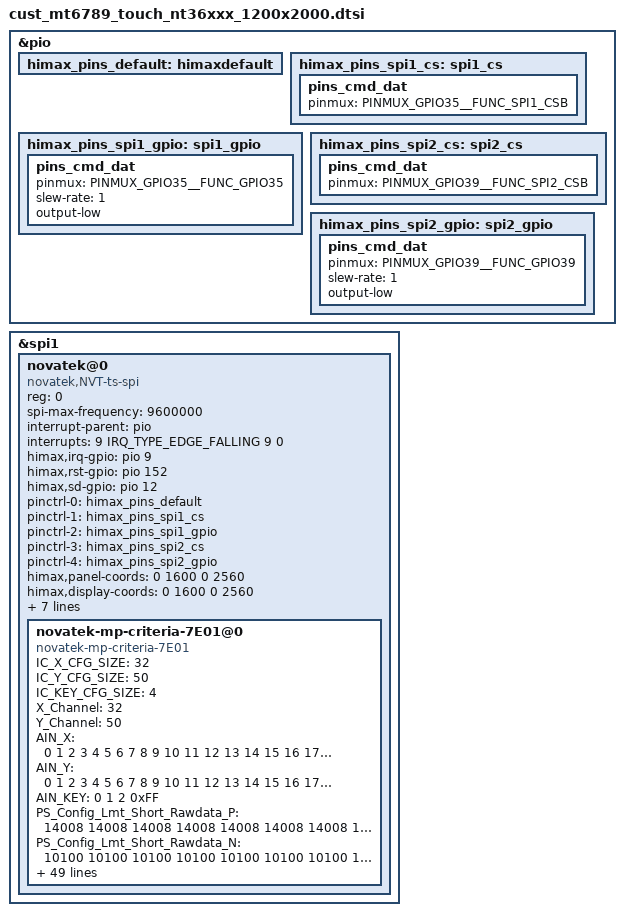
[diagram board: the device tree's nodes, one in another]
// SPDX-License-Identifier: GPL-2.0
/*
 * Copyright (c) 2022 MediaTek Inc.
 *
 */

&pio {
	himax_pins_default: himaxdefault {
	};

	himax_pins_spi1_cs: spi1_cs {
		pins_cmd_dat {
			pinmux = <PINMUX_GPIO35__FUNC_SPI1_CSB>;
		};
	};

	himax_pins_spi1_gpio: spi1_gpio {
		pins_cmd_dat {
			pinmux = <PINMUX_GPIO35__FUNC_GPIO35>;
			slew-rate = <1>;
			output-low;
		};
	};
	himax_pins_spi2_cs: spi2_cs {
		pins_cmd_dat {
			pinmux = <PINMUX_GPIO39__FUNC_SPI2_CSB>;
		};
	};

	himax_pins_spi2_gpio: spi2_gpio {
		pins_cmd_dat {
			pinmux = <PINMUX_GPIO39__FUNC_GPIO39>;
			slew-rate = <1>;
			output-low;
		};
	};
};

&spi1 {
	status = "okay";
	#address-cells = <1>;
	#size-cells = <0>;
	novatek@0{
		compatible = "novatek,NVT-ts-spi";//,"himax,hxcommon" ;
		reg = <0>; //Same as CS ID
		status = "okay";
		//4800000,9600000,15000000,19200000
		spi-max-frequency = <9600000>;	
        interrupt-parent = <&pio>;
        interrupts = <9 IRQ_TYPE_EDGE_FALLING 9 0>;
        himax,irq-gpio = <&pio 9 0x0>;
        himax,rst-gpio = <&pio 152 0x0>;
        himax,sd-gpio = <&pio 12 0x0>;
        pinctrl-names = "default", "spi1_cs", "spi1_gpio", "spi2_cs", "spi2_gpio";
        pinctrl-0 = <&himax_pins_default>;
        pinctrl-1 = <&himax_pins_spi1_cs>;
        pinctrl-2 = <&himax_pins_spi1_gpio>;
        pinctrl-3 = <&himax_pins_spi2_cs>;
        pinctrl-4 = <&himax_pins_spi2_gpio>;
        himax,panel-coords = <0 1600 0 2560>;
        himax,display-coords = <0 1600 0 2560>;
		novatek,reset-gpio = <&pio 152 0x00>;
		novatek,irq-gpio = <&pio 9 0x00>;
		novatek,pen-support;
		novatek,stylus-resol-double;
		
	  /* 525 */
		//novatek,swrst-n8-addr = <0x01F01A>;
		/* 672A, 525B, 675, 526 */
		novatek,swrst-n8-addr = <0x03F0FE>;
		novatek,spi-rd-fast-addr = <0x03F310>;
		
		/* MP */
		novatek,mp-support-dt;
		
		novatek-mp-criteria-7E01@0 {
			#address-cells = <1>;
			#size-cells = <0>;
			compatible = "novatek-mp-criteria-7E01";

			/* MP Config */
			IC_X_CFG_SIZE = <32>;
			IC_Y_CFG_SIZE = <50>;
			IC_KEY_CFG_SIZE = <4>;
			X_Channel = <32>;
			Y_Channel = <50>;
			AIN_X = <0 1 2 3 4 5 6 7 8 9 10 11 12 13 14 15 16 17 18 19 20 21 22 23 24 25 26 27 28 29 30 31>;
			AIN_Y = <0 1 2 3 4 5 6 7 8 9 10 11 12 13 14 15 16 17 18 19 20 21 22 23 24 25 26 27 28 29 30 31 32 33 34 35 36 37 38 39 40 41 42 43 44 45 46 47 48 49>;
			AIN_KEY = <0 1 2 0xFF>;

			/* MP Criteria */
			PS_Config_Lmt_Short_Rawdata_P = <
				14008 14008 14008 14008 14008 14008 14008 14008 14008 14008 14008 14008 14008 14008 14008 14008 14008 14008 14008 14008 14008 14008 14008 14008 14008 14008 14008 14008 14008 14008 14008 14008
				14008 14008 14008 14008 14008 14008 14008 14008 14008 14008 14008 14008 14008 14008 14008 14008 14008 14008 14008 14008 14008 14008 14008 14008 14008 14008 14008 14008 14008 14008 14008 14008
				14008 14008 14008 14008 14008 14008 14008 14008 14008 14008 14008 14008 14008 14008 14008 14008 14008 14008 14008 14008 14008 14008 14008 14008 14008 14008 14008 14008 14008 14008 14008 14008
				14008 14008 14008 14008 14008 14008 14008 14008 14008 14008 14008 14008 14008 14008 14008 14008 14008 14008 14008 14008 14008 14008 14008 14008 14008 14008 14008 14008 14008 14008 14008 14008
				14008 14008 14008 14008 14008 14008 14008 14008 14008 14008 14008 14008 14008 14008 14008 14008 14008 14008 14008 14008 14008 14008 14008 14008 14008 14008 14008 14008 14008 14008 14008 14008
				14008 14008 14008 14008 14008 14008 14008 14008 14008 14008 14008 14008 14008 14008 14008 14008 14008 14008 14008 14008 14008 14008 14008 14008 14008 14008 14008 14008 14008 14008 14008 14008
				14008 14008 14008 14008 14008 14008 14008 14008 14008 14008 14008 14008 14008 14008 14008 14008 14008 14008 14008 14008 14008 14008 14008 14008 14008 14008 14008 14008 14008 14008 14008 14008
				14008 14008 14008 14008 14008 14008 14008 14008 14008 14008 14008 14008 14008 14008 14008 14008 14008 14008 14008 14008 14008 14008 14008 14008 14008 14008 14008 14008 14008 14008 14008 14008
				14008 14008 14008 14008 14008 14008 14008 14008 14008 14008 14008 14008 14008 14008 14008 14008 14008 14008 14008 14008 14008 14008 14008 14008 14008 14008 14008 14008 14008 14008 14008 14008
				14008 14008 14008 14008 14008 14008 14008 14008 14008 14008 14008 14008 14008 14008 14008 14008 14008 14008 14008 14008 14008 14008 14008 14008 14008 14008 14008 14008 14008 14008 14008 14008
				14008 14008 14008 14008 14008 14008 14008 14008 14008 14008 14008 14008 14008 14008 14008 14008 14008 14008 14008 14008 14008 14008 14008 14008 14008 14008 14008 14008 14008 14008 14008 14008
				14008 14008 14008 14008 14008 14008 14008 14008 14008 14008 14008 14008 14008 14008 14008 14008 14008 14008 14008 14008 14008 14008 14008 14008 14008 14008 14008 14008 14008 14008 14008 14008
				14008 14008 14008 14008 14008 14008 14008 14008 14008 14008 14008 14008 14008 14008 14008 14008 14008 14008 14008 14008 14008 14008 14008 14008 14008 14008 14008 14008 14008 14008 14008 14008
				14008 14008 14008 14008 14008 14008 14008 14008 14008 14008 14008 14008 14008 14008 14008 14008 14008 14008 14008 14008 14008 14008 14008 14008 14008 14008 14008 14008 14008 14008 14008 14008
				14008 14008 14008 14008 14008 14008 14008 14008 14008 14008 14008 14008 14008 14008 14008 14008 14008 14008 14008 14008 14008 14008 14008 14008 14008 14008 14008 14008 14008 14008 14008 14008
				14008 14008 14008 14008 14008 14008 14008 14008 14008 14008 14008 14008 14008 14008 14008 14008 14008 14008 14008 14008 14008 14008 14008 14008 14008 14008 14008 14008 14008 14008 14008 14008
				14008 14008 14008 14008 14008 14008 14008 14008 14008 14008 14008 14008 14008 14008 14008 14008 14008 14008 14008 14008 14008 14008 14008 14008 14008 14008 14008 14008 14008 14008 14008 14008
				14008 14008 14008 14008 14008 14008 14008 14008 14008 14008 14008 14008 14008 14008 14008 14008 14008 14008 14008 14008 14008 14008 14008 14008 14008 14008 14008 14008 14008 14008 14008 14008
				14008 14008 14008 14008 14008 14008 14008 14008 14008 14008 14008 14008 14008 14008 14008 14008 14008 14008 14008 14008 14008 14008 14008 14008 14008 14008 14008 14008 14008 14008 14008 14008
				14008 14008 14008 14008 14008 14008 14008 14008 14008 14008 14008 14008 14008 14008 14008 14008 14008 14008 14008 14008 14008 14008 14008 14008 14008 14008 14008 14008 14008 14008 14008 14008
				14008 14008 14008 14008 14008 14008 14008 14008 14008 14008 14008 14008 14008 14008 14008 14008 14008 14008 14008 14008 14008 14008 14008 14008 14008 14008 14008 14008 14008 14008 14008 14008
				14008 14008 14008 14008 14008 14008 14008 14008 14008 14008 14008 14008 14008 14008 14008 14008 14008 14008 14008 14008 14008 14008 14008 14008 14008 14008 14008 14008 14008 14008 14008 14008
				14008 14008 14008 14008 14008 14008 14008 14008 14008 14008 14008 14008 14008 14008 14008 14008 14008 14008 14008 14008 14008 14008 14008 14008 14008 14008 14008 14008 14008 14008 14008 14008
				14008 14008 14008 14008 14008 14008 14008 14008 14008 14008 14008 14008 14008 14008 14008 14008 14008 14008 14008 14008 14008 14008 14008 14008 14008 14008 14008 14008 14008 14008 14008 14008
				14008 14008 14008 14008 14008 14008 14008 14008 14008 14008 14008 14008 14008 14008 14008 14008 14008 14008 14008 14008 14008 14008 14008 14008 14008 14008 14008 14008 14008 14008 14008 14008
				14008 14008 14008 14008 14008 14008 14008 14008 14008 14008 14008 14008 14008 14008 14008 14008 14008 14008 14008 14008 14008 14008 14008 14008 14008 14008 14008 14008 14008 14008 14008 14008
				14008 14008 14008 14008 14008 14008 14008 14008 14008 14008 14008 14008 14008 14008 14008 14008 14008 14008 14008 14008 14008 14008 14008 14008 14008 14008 14008 14008 14008 14008 14008 14008
				14008 14008 14008 14008 14008 14008 14008 14008 14008 14008 14008 14008 14008 14008 14008 14008 14008 14008 14008 14008 14008 14008 14008 14008 14008 14008 14008 14008 14008 14008 14008 14008
				14008 14008 14008 14008 14008 14008 14008 14008 14008 14008 14008 14008 14008 14008 14008 14008 14008 14008 14008 14008 14008 14008 14008 14008 14008 14008 14008 14008 14008 14008 14008 14008
				14008 14008 14008 14008 14008 14008 14008 14008 14008 14008 14008 14008 14008 14008 14008 14008 14008 14008 14008 14008 14008 14008 14008 14008 14008 14008 14008 14008 14008 14008 14008 14008
				14008 14008 14008 14008 14008 14008 14008 14008 14008 14008 14008 14008 14008 14008 14008 14008 14008 14008 14008 14008 14008 14008 14008 14008 14008 14008 14008 14008 14008 14008 14008 14008
				14008 14008 14008 14008 14008 14008 14008 14008 14008 14008 14008 14008 14008 14008 14008 14008 14008 14008 14008 14008 14008 14008 14008 14008 14008 14008 14008 14008 14008 14008 14008 14008
				14008 14008 14008 14008 14008 14008 14008 14008 14008 14008 14008 14008 14008 14008 14008 14008 14008 14008 14008 14008 14008 14008 14008 14008 14008 14008 14008 14008 14008 14008 14008 14008
				14008 14008 14008 14008 14008 14008 14008 14008 14008 14008 14008 14008 14008 14008 14008 14008 14008 14008 14008 14008 14008 14008 14008 14008 14008 14008 14008 14008 14008 14008 14008 14008
				14008 14008 14008 14008 14008 14008 14008 14008 14008 14008 14008 14008 14008 14008 14008 14008 14008 14008 14008 14008 14008 14008 14008 14008 14008 14008 14008 14008 14008 14008 14008 14008
				14008 14008 14008 14008 14008 14008 14008 14008 14008 14008 14008 14008 14008 14008 14008 14008 14008 14008 14008 14008 14008 14008 14008 14008 14008 14008 14008 14008 14008 14008 14008 14008
				14008 14008 14008 14008 14008 14008 14008 14008 14008 14008 14008 14008 14008 14008 14008 14008 14008 14008 14008 14008 14008 14008 14008 14008 14008 14008 14008 14008 14008 14008 14008 14008
				14008 14008 14008 14008 14008 14008 14008 14008 14008 14008 14008 14008 14008 14008 14008 14008 14008 14008 14008 14008 14008 14008 14008 14008 14008 14008 14008 14008 14008 14008 14008 14008
				14008 14008 14008 14008 14008 14008 14008 14008 14008 14008 14008 14008 14008 14008 14008 14008 14008 14008 14008 14008 14008 14008 14008 14008 14008 14008 14008 14008 14008 14008 14008 14008
				14008 14008 14008 14008 14008 14008 14008 14008 14008 14008 14008 14008 14008 14008 14008 14008 14008 14008 14008 14008 14008 14008 14008 14008 14008 14008 14008 14008 14008 14008 14008 14008
				14008 14008 14008 14008 14008 14008 14008 14008 14008 14008 14008 14008 14008 14008 14008 14008 14008 14008 14008 14008 14008 14008 14008 14008 14008 14008 14008 14008 14008 14008 14008 14008
				14008 14008 14008 14008 14008 14008 14008 14008 14008 14008 14008 14008 14008 14008 14008 14008 14008 14008 14008 14008 14008 14008 14008 14008 14008 14008 14008 14008 14008 14008 14008 14008
				14008 14008 14008 14008 14008 14008 14008 14008 14008 14008 14008 14008 14008 14008 14008 14008 14008 14008 14008 14008 14008 14008 14008 14008 14008 14008 14008 14008 14008 14008 14008 14008
				14008 14008 14008 14008 14008 14008 14008 14008 14008 14008 14008 14008 14008 14008 14008 14008 14008 14008 14008 14008 14008 14008 14008 14008 14008 14008 14008 14008 14008 14008 14008 14008
				14008 14008 14008 14008 14008 14008 14008 14008 14008 14008 14008 14008 14008 14008 14008 14008 14008 14008 14008 14008 14008 14008 14008 14008 14008 14008 14008 14008 14008 14008 14008 14008
				14008 14008 14008 14008 14008 14008 14008 14008 14008 14008 14008 14008 14008 14008 14008 14008 14008 14008 14008 14008 14008 14008 14008 14008 14008 14008 14008 14008 14008 14008 14008 14008
				14008 14008 14008 14008 14008 14008 14008 14008 14008 14008 14008 14008 14008 14008 14008 14008 14008 14008 14008 14008 14008 14008 14008 14008 14008 14008 14008 14008 14008 14008 14008 14008
				14008 14008 14008 14008 14008 14008 14008 14008 14008 14008 14008 14008 14008 14008 14008 14008 14008 14008 14008 14008 14008 14008 14008 14008 14008 14008 14008 14008 14008 14008 14008 14008
				14008 14008 14008 14008 14008 14008 14008 14008 14008 14008 14008 14008 14008 14008 14008 14008 14008 14008 14008 14008 14008 14008 14008 14008 14008 14008 14008 14008 14008 14008 14008 14008
				14008 14008 14008 14008 14008 14008 14008 14008 14008 14008 14008 14008 14008 14008 14008 14008 14008 14008 14008 14008 14008 14008 14008 14008 14008 14008 14008 14008 14008 14008 14008 14008
				14008 14008 14008>;

			PS_Config_Lmt_Short_Rawdata_N = <
				10100 10100 10100 10100 10100 10100 10100 10100 10100 10100 10100 10100 10100 10100 10100 10100 10100 10100 10100 10100 10100 10100 10100 10100 10100 10100 10100 10100 10100 10100 10100 10100
				10100 10100 10100 10100 10100 10100 10100 10100 10100 10100 10100 10100 10100 10100 10100 10100 10100 10100 10100 10100 10100 10100 10100 10100 10100 10100 10100 10100 10100 10100 10100 10100
				10100 10100 10100 10100 10100 10100 10100 10100 10100 10100 10100 10100 10100 10100 10100 10100 10100 10100 10100 10100 10100 10100 10100 10100 10100 10100 10100 10100 10100 10100 10100 10100
				10100 10100 10100 10100 10100 10100 10100 10100 10100 10100 10100 10100 10100 10100 10100 10100 10100 10100 10100 10100 10100 10100 10100 10100 10100 10100 10100 10100 10100 10100 10100 10100
				10100 10100 10100 10100 10100 10100 10100 10100 10100 10100 10100 10100 10100 10100 10100 10100 10100 10100 10100 10100 10100 10100 10100 10100 10100 10100 10100 10100 10100 10100 10100 10100
				10100 10100 10100 10100 10100 10100 10100 10100 10100 10100 10100 10100 10100 10100 10100 10100 10100 10100 10100 10100 10100 10100 10100 10100 10100 10100 10100 10100 10100 10100 10100 10100
				10100 10100 10100 10100 10100 10100 10100 10100 10100 10100 10100 10100 10100 10100 10100 10100 10100 10100 10100 10100 10100 10100 10100 10100 10100 10100 10100 10100 10100 10100 10100 10100
				10100 10100 10100 10100 10100 10100 10100 10100 10100 10100 10100 10100 10100 10100 10100 10100 10100 10100 10100 10100 10100 10100 10100 10100 10100 10100 10100 10100 10100 10100 10100 10100
				10100 10100 10100 10100 10100 10100 10100 10100 10100 10100 10100 10100 10100 10100 10100 10100 10100 10100 10100 10100 10100 10100 10100 10100 10100 10100 10100 10100 10100 10100 10100 10100
				10100 10100 10100 10100 10100 10100 10100 10100 10100 10100 10100 10100 10100 10100 10100 10100 10100 10100 10100 10100 10100 10100 10100 10100 10100 10100 10100 10100 10100 10100 10100 10100
				10100 10100 10100 10100 10100 10100 10100 10100 10100 10100 10100 10100 10100 10100 10100 10100 10100 10100 10100 10100 10100 10100 10100 10100 10100 10100 10100 10100 10100 10100 10100 10100
				10100 10100 10100 10100 10100 10100 10100 10100 10100 10100 10100 10100 10100 10100 10100 10100 10100 10100 10100 10100 10100 10100 10100 10100 10100 10100 10100 10100 10100 10100 10100 10100
				10100 10100 10100 10100 10100 10100 10100 10100 10100 10100 10100 10100 10100 10100 10100 10100 10100 10100 10100 10100 10100 10100 10100 10100 10100 10100 10100 10100 10100 10100 10100 10100
				10100 10100 10100 10100 10100 10100 10100 10100 10100 10100 10100 10100 10100 10100 10100 10100 10100 10100 10100 10100 10100 10100 10100 10100 10100 10100 10100 10100 10100 10100 10100 10100
				10100 10100 10100 10100 10100 10100 10100 10100 10100 10100 10100 10100 10100 10100 10100 10100 10100 10100 10100 10100 10100 10100 10100 10100 10100 10100 10100 10100 10100 10100 10100 10100
				10100 10100 10100 10100 10100 10100 10100 10100 10100 10100 10100 10100 10100 10100 10100 10100 10100 10100 10100 10100 10100 10100 10100 10100 10100 10100 10100 10100 10100 10100 10100 10100
				10100 10100 10100 10100 10100 10100 10100 10100 10100 10100 10100 10100 10100 10100 10100 10100 10100 10100 10100 10100 10100 10100 10100 10100 10100 10100 10100 10100 10100 10100 10100 10100
				10100 10100 10100 10100 10100 10100 10100 10100 10100 10100 10100 10100 10100 10100 10100 10100 10100 10100 10100 10100 10100 10100 10100 10100 10100 10100 10100 10100 10100 10100 10100 10100
				10100 10100 10100 10100 10100 10100 10100 10100 10100 10100 10100 10100 10100 10100 10100 10100 10100 10100 10100 10100 10100 10100 10100 10100 10100 10100 10100 10100 10100 10100 10100 10100
				10100 10100 10100 10100 10100 10100 10100 10100 10100 10100 10100 10100 10100 10100 10100 10100 10100 10100 10100 10100 10100 10100 10100 10100 10100 10100 10100 10100 10100 10100 10100 10100
				10100 10100 10100 10100 10100 10100 10100 10100 10100 10100 10100 10100 10100 10100 10100 10100 10100 10100 10100 10100 10100 10100 10100 10100 10100 10100 10100 10100 10100 10100 10100 10100
				10100 10100 10100 10100 10100 10100 10100 10100 10100 10100 10100 10100 10100 10100 10100 10100 10100 10100 10100 10100 10100 10100 10100 10100 10100 10100 10100 10100 10100 10100 10100 10100
				10100 10100 10100 10100 10100 10100 10100 10100 10100 10100 10100 10100 10100 10100 10100 10100 10100 10100 10100 10100 10100 10100 10100 10100 10100 10100 10100 10100 10100 10100 10100 10100
				10100 10100 10100 10100 10100 10100 10100 10100 10100 10100 10100 10100 10100 10100 10100 10100 10100 10100 10100 10100 10100 10100 10100 10100 10100 10100 10100 10100 10100 10100 10100 10100
				10100 10100 10100 10100 10100 10100 10100 10100 10100 10100 10100 10100 10100 10100 10100 10100 10100 10100 10100 10100 10100 10100 10100 10100 10100 10100 10100 10100 10100 10100 10100 10100
				10100 10100 10100 10100 10100 10100 10100 10100 10100 10100 10100 10100 10100 10100 10100 10100 10100 10100 10100 10100 10100 10100 10100 10100 10100 10100 10100 10100 10100 10100 10100 10100
				10100 10100 10100 10100 10100 10100 10100 10100 10100 10100 10100 10100 10100 10100 10100 10100 10100 10100 10100 10100 10100 10100 10100 10100 10100 10100 10100 10100 10100 10100 10100 10100
				10100 10100 10100 10100 10100 10100 10100 10100 10100 10100 10100 10100 10100 10100 10100 10100 10100 10100 10100 10100 10100 10100 10100 10100 10100 10100 10100 10100 10100 10100 10100 10100
				10100 10100 10100 10100 10100 10100 10100 10100 10100 10100 10100 10100 10100 10100 10100 10100 10100 10100 10100 10100 10100 10100 10100 10100 10100 10100 10100 10100 10100 10100 10100 10100
				10100 10100 10100 10100 10100 10100 10100 10100 10100 10100 10100 10100 10100 10100 10100 10100 10100 10100 10100 10100 10100 10100 10100 10100 10100 10100 10100 10100 10100 10100 10100 10100
				10100 10100 10100 10100 10100 10100 10100 10100 10100 10100 10100 10100 10100 10100 10100 10100 10100 10100 10100 10100 10100 10100 10100 10100 10100 10100 10100 10100 10100 10100 10100 10100
				10100 10100 10100 10100 10100 10100 10100 10100 10100 10100 10100 10100 10100 10100 10100 10100 10100 10100 10100 10100 10100 10100 10100 10100 10100 10100 10100 10100 10100 10100 10100 10100
				10100 10100 10100 10100 10100 10100 10100 10100 10100 10100 10100 10100 10100 10100 10100 10100 10100 10100 10100 10100 10100 10100 10100 10100 10100 10100 10100 10100 10100 10100 10100 10100
				10100 10100 10100 10100 10100 10100 10100 10100 10100 10100 10100 10100 10100 10100 10100 10100 10100 10100 10100 10100 10100 10100 10100 10100 10100 10100 10100 10100 10100 10100 10100 10100
				10100 10100 10100 10100 10100 10100 10100 10100 10100 10100 10100 10100 10100 10100 10100 10100 10100 10100 10100 10100 10100 10100 10100 10100 10100 10100 10100 10100 10100 10100 10100 10100
				10100 10100 10100 10100 10100 10100 10100 10100 10100 10100 10100 10100 10100 10100 10100 10100 10100 10100 10100 10100 10100 10100 10100 10100 10100 10100 10100 10100 10100 10100 10100 10100
				10100 10100 10100 10100 10100 10100 10100 10100 10100 10100 10100 10100 10100 10100 10100 10100 10100 10100 10100 10100 10100 10100 10100 10100 10100 10100 10100 10100 10100 10100 10100 10100
				10100 10100 10100 10100 10100 10100 10100 10100 10100 10100 10100 10100 10100 10100 10100 10100 10100 10100 10100 10100 10100 10100 10100 10100 10100 10100 10100 10100 10100 10100 10100 10100
				10100 10100 10100 10100 10100 10100 10100 10100 10100 10100 10100 10100 10100 10100 10100 10100 10100 10100 10100 10100 10100 10100 10100 10100 10100 10100 10100 10100 10100 10100 10100 10100
				10100 10100 10100 10100 10100 10100 10100 10100 10100 10100 10100 10100 10100 10100 10100 10100 10100 10100 10100 10100 10100 10100 10100 10100 10100 10100 10100 10100 10100 10100 10100 10100
				10100 10100 10100 10100 10100 10100 10100 10100 10100 10100 10100 10100 10100 10100 10100 10100 10100 10100 10100 10100 10100 10100 10100 10100 10100 10100 10100 10100 10100 10100 10100 10100
				10100 10100 10100 10100 10100 10100 10100 10100 10100 10100 10100 10100 10100 10100 10100 10100 10100 10100 10100 10100 10100 10100 10100 10100 10100 10100 10100 10100 10100 10100 10100 10100
				10100 10100 10100 10100 10100 10100 10100 10100 10100 10100 10100 10100 10100 10100 10100 10100 10100 10100 10100 10100 10100 10100 10100 10100 10100 10100 10100 10100 10100 10100 10100 10100
				10100 10100 10100 10100 10100 10100 10100 10100 10100 10100 10100 10100 10100 10100 10100 10100 10100 10100 10100 10100 10100 10100 10100 10100 10100 10100 10100 10100 10100 10100 10100 10100
				10100 10100 10100 10100 10100 10100 10100 10100 10100 10100 10100 10100 10100 10100 10100 10100 10100 10100 10100 10100 10100 10100 10100 10100 10100 10100 10100 10100 10100 10100 10100 10100
				10100 10100 10100 10100 10100 10100 10100 10100 10100 10100 10100 10100 10100 10100 10100 10100 10100 10100 10100 10100 10100 10100 10100 10100 10100 10100 10100 10100 10100 10100 10100 10100
				10100 10100 10100 10100 10100 10100 10100 10100 10100 10100 10100 10100 10100 10100 10100 10100 10100 10100 10100 10100 10100 10100 10100 10100 10100 10100 10100 10100 10100 10100 10100 10100
				10100 10100 10100 10100 10100 10100 10100 10100 10100 10100 10100 10100 10100 10100 10100 10100 10100 10100 10100 10100 10100 10100 10100 10100 10100 10100 10100 10100 10100 10100 10100 10100
				10100 10100 10100 10100 10100 10100 10100 10100 10100 10100 10100 10100 10100 10100 10100 10100 10100 10100 10100 10100 10100 10100 10100 10100 10100 10100 10100 10100 10100 10100 10100 10100
				10100 10100 10100 10100 10100 10100 10100 10100 10100 10100 10100 10100 10100 10100 10100 10100 10100 10100 10100 10100 10100 10100 10100 10100 10100 10100 10100 10100 10100 10100 10100 10100
				10100 10100 10100>;

			PS_Config_Lmt_Open_Rawdata_P = <
				3326	3243	3187	3136	3101	3060	3017	2977	2913	2962	2993	3032	3061	3108	3171	3229	3140	3091	3035	2979	2941	2898	2860	2808	2872	2902	2930	2970	3001	3046	3110	3166
			3340	3256	3197	3147	3109	3068	3022	2993	2898	2920	2956	2997	3029	3075	3129	3196	3169	3117	3061	3007	2975	2931	2886	2856	2788	2809	2849	2886	2917	2959	3019	3074
			3367	3281	3222	3172	3138	3094	3045	3014	2993	3021	3057	3087	3129	3173	3228	3299	3208	3150	3096	3045	3012	2968	2921	2891	2896	2920	2962	2993	3033	3080	3138	3208
			3360	3278	3220	3171	3134	3095	3047	3019	2921	2947	2983	3017	3056	3105	3159	3227	3166	3112	3049	3003	2965	2930	2881	2851	2844	2870	2907	2941	2980	3024	3080	3140
			3409	3323	3260	3215	3171	3126	3082	3057	2966	2998	3025	3067	3106	3154	3210	3278	3249	3189	3124	3078	3038	2993	2952	2924	2898	2928	2962	3003	3042	3084	3140	3201
			3383	3304	3245	3197	3161	3116	3074	3042	2931	2969	3000	3039	3077	3124	3180	3245	3208	3151	3091	3040	3004	2962	2923	2888	2864	2895	2928	2968	3007	3053	3108	3169
			3416	3334	3277	3228	3187	3154	3101	3074	2979	3012	3040	3084	3120	3169	3222	3290	3249	3187	3138	3085	3046	3011	2961	2933	2878	2909	2945	2984	3022	3070	3123	3185
			3389	3304	3246	3194	3157	3117	3067	2868	2997	3026	3063	3102	3129	3176	3245	3117	3234	3169	3112	3060	3021	2983	2931	2735	2914	2937	2979	3019	3047	3094	3162	3035
			3382	3309	3249	3204	3166	3123	3080	3054	2975	3010	3047	3084	3112	3159	3214	3274	3210	3166	3106	3061	3025	2979	2940	2916	2941	2972	3019	3059	3084	3131	3189	3239
			3446	3379	3315	3262	3228	3183	3138	3112	3001	3036	3075	3102	3140	3189	3243	3302	3302	3260	3199	3145	3116	3074	3031	3004	2902	2928	2975	3004	3040	3085	3141	3196
			3409	3343	3283	3234	3200	3159	2962	3084	3060	3091	3129	3158	3199	3241	3141	3351	3257	3220	3159	3106	3074	3032	2843	2965	2982	3007	3049	3081	3115	3158	3066	3260
			3448	3378	3322	3271	3231	3193	3119	3109	3018	3049	3075	3116	3154	3199	3227	3305	3292	3250	3197	3145	3109	3074	3008	2994	2914	2940	2975	3017	3056	3102	3131	3208
			3427	3372	3308	3263	3222	3189	3141	3106	3070	3102	3133	3172	3211	3259	3316	3348	3280	3249	3189	3145	3103	3068	3028	2991	3007	3035	3071	3112	3148	3197	3250	3276
			3449	3400	3337	3290	3257	3222	3166	3140	3056	3074	3113	3155	3178	3239	3297	3325	3290	3266	3204	3151	3119	3087	3031	3008	2977	2989	3035	3075	3096	3155	3211	3231
			3465	3417	3360	3311	3276	3057	3183	3161	3112	3136	3175	3217	3243	3106	3364	3385	3304	3274	3214	3161	3126	2907	3035	3012	3047	3061	3109	3148	3172	3038	3288	3306
			3425	3378	3316	3266	3231	3194	3138	3116	3067	3098	3137	3159	3199	3245	3299	3330	3285	3260	3203	3151	3117	3082	3031	3005	2977	3001	3049	3075	3113	3161	3214	3241
			3505	3460	3396	3346	3312	3264	3217	3194	3147	3180	3222	3249	3287	3334	3389	3418	3355	3337	3271	3220	3192	3144	3102	3077	3042	3064	3113	3140	3178	3222	3277	3304
			3459	3420	3357	3309	3280	3235	3187	3151	3101	3131	3164	3201	3241	3288	3346	3369	3327	3311	3249	3197	3165	3119	3078	3038	3025	3049	3081	3123	3158	3206	3262	3285
			3553	3508	3459	3410	3180	3329	3280	3245	3151	3183	3213	3253	3101	3337	3396	3409	3376	3358	3308	3256	3031	3178	3137	3099	3064	3091	3129	3169	3018	3252	3308	3319
			3511	3467	3402	3361	3319	3281	3221	3201	3161	3178	3221	3257	3290	3340	3400	3409	3360	3339	3278	3238	3196	3157	3099	3078	3067	3080	3131	3168	3199	3250	3309	3312
			3586	3558	3497	3442	3410	3374	3312	3292	3147	3162	3204	3241	3271	3322	3379	3382	3382	3378	3316	3263	3232	3196	3141	3116	3063	3074	3122	3158	3192	3241	3298	3302
			3505	3477	3414	3176	3329	3277	3229	3208	3203	3234	3276	3119	3340	3390	3449	3448	3332	3326	3263	3022	3179	3130	3088	3063	3101	3127	3173	3022	3239	3291	3355	3353
			3547	3530	3476	3421	3386	3337	3287	3266	3201	3228	3269	3301	3332	3382	3431	3424	3393	3399	3344	3292	3259	3210	3171	3147	3110	3131	3179	3214	3243	3292	3347	3336
			3592	3574	3518	3466	3434	3386	3337	3311	3187	3214	3257	3291	3334	3371	3420	3425	3416	3423	3368	3315	3283	3235	3193	3162	3103	3124	3171	3206	3248	3281	3329	3329
			3550	3518	3500	3449	3400	3362	3312	3284	3292	3320	3360	3393	3439	3490	3504	3514	3399	3395	3375	3323	3280	3242	3201	3168	3186	3210	3255	3290	3333	3386	3403	3407
			3535	3502	3288	3437	3389	3353	3304	3277	3224	3246	3099	3332	3357	3409	3431	3420	3402	3390	3169	3322	3274	3238	3193	3162	3120	3138	3000	3231	3259	3312	3336	3322
			3598	3579	3554	3505	3466	3430	3374	3347	3330	3354	3392	3435	3467	3518	3537	3532	3404	3411	3385	3337	3302	3269	3225	3194	3218	3236	3278	3326	3357	3404	3425	3418
			3557	3539	3518	3466	3430	3390	3339	3311	3259	3281	3332	3364	3396	3445	3460	3451	3372	3378	3358	3305	3270	3234	3193	3159	3150	3166	3221	3253	3285	3337	3354	3346
			3648	3626	3609	3557	3523	3481	3427	3409	3311	3327	3382	3418	3446	3494	3504	3493	3491	3498	3484	3431	3397	3360	3313	3295	3196	3208	3267	3304	3332	3382	3399	3385
			3560	3350	3528	3474	3435	3396	3354	3326	3290	3131	3362	3395	3437	3487	3481	3486	3417	3232	3410	3355	3318	3278	3246	3213	3217	3061	3290	3326	3368	3421	3417	3421
			3669	3642	3640	3586	3549	3504	3459	3430	3316	3350	3392	3424	3462	3512	3502	3505	3528	3525	3523	3467	3431	3389	3357	3323	3215	3248	3290	3323	3364	3414	3410	3410
			3595	3563	3561	3512	3472	3430	3389	3361	3382	3404	3446	3488	3515	3567	3567	3556	3455	3455	3455	3404	3364	3323	3290	3259	3299	3319	3364	3409	3437	3487	3490	3477
			3403	3567	3568	3526	3483	3453	3403	3375	3193	3407	3448	3493	3522	3564	3556	3549	3236	3425	3434	3389	3347	3319	3274	3246	3078	3288	3329	3371	3403	3444	3442	3435
			3661	3628	3633	3592	3547	3519	3466	3446	3382	3404	3456	3486	3519	3557	3550	3543	3536	3535	3543	3501	3460	3432	3390	3369	3262	3284	3334	3368	3399	3435	3431	3421
			3640	3620	3610	3571	3543	3498	3446	3427	3445	3466	3521	3554	3584	3620	3614	3603	3477	3490	3480	3444	3416	3376	3334	3313	3348	3369	3421	3459	3488	3526	3522	3502
			3665	3645	3645	3600	3571	3529	3479	3458	3410	3439	3481	3516	3544	3577	3570	3567	3556	3567	3574	3525	3495	3455	3411	3386	3290	3318	3358	3395	3423	3456	3453	3448
			3700	3665	3666	3634	3592	3546	3507	3474	3491	3525	3568	3600	3637	3665	3654	3649	3507	3505	3511	3479	3439	3397	3364	3332	3375	3411	3452	3486	3526	3553	3544	3544
			3710	3670	3673	3645	3605	3561	3519	3487	3446	3469	3512	3542	3578	3602	3596	3585	3553	3547	3553	3525	3484	3442	3411	3376	3343	3362	3403	3442	3477	3501	3500	3487
			3722	3690	3694	3670	3630	3595	3549	3515	3525	3547	3589	3630	3662	3682	3676	3669	3586	3584	3589	3567	3522	3495	3456	3416	3406	3425	3472	3514	3544	3565	3564	3558
			3682	3647	3647	3624	3582	3550	3500	3467	3500	3519	3561	3599	3630	3645	3641	3634	3553	3549	3553	3532	3491	3460	3424	3388	3375	3397	3439	3481	3512	3532	3529	3521
			3770	3747	3735	3712	3684	3640	3591	3564	3544	3565	3616	3651	3682	3697	3690	3687	3640	3652	3642	3624	3593	3556	3511	3481	3399	3418	3469	3505	3535	3550	3550	3544
			3694	3670	3670	3645	3614	3574	3528	3502	3509	3530	3577	3610	3645	3654	3641	3640	3565	3575	3577	3549	3518	3480	3441	3416	3423	3448	3495	3532	3570	3584	3575	3577
			3827	3788	3788	3777	3735	3687	3649	3617	3537	3568	3607	3640	3676	3683	3672	3670	3663	3658	3659	3647	3603	3561	3530	3497	3414	3444	3484	3519	3557	3565	3558	3556
			3754	3715	3717	3707	3666	3624	3586	3556	3558	3586	3626	3666	3696	3700	3691	3684	3609	3600	3605	3596	3553	3511	3483	3448	3474	3507	3546	3589	3619	3624	3624	3614
			3836	3801	3801	3795	3752	3707	3670	3635	3556	3579	3621	3661	3690	3690	3683	3677	3693	3689	3693	3689	3642	3606	3572	3537	3455	3480	3521	3561	3593	3595	3589	3586
			3792	3756	3756	3752	3707	3670	3628	3598	3655	3680	3725	3763	3803	3789	3785	3789	3634	3626	3631	3627	3585	3551	3518	3487	3546	3570	3616	3651	3690	3679	3673	3673
			3791	3757	3757	3766	3726	3689	3644	3616	3645	3673	3718	3750	3784	3774	3763	3760	3614	3609	3612	3621	3584	3549	3509	3480	3539	3567	3613	3644	3677	3676	3665	3661
			3840	3805	3803	3810	3780	3736	3694	3666	3585	3617	3658	3694	3719	3711	3708	3703	3680	3676	3673	3682	3654	3612	3575	3547	3474	3509	3549	3584	3607	3598	3596	3593
			3782	3749	3749	3752	3722	3679	3640	3606	3677	3711	3749	3788	3813	3801	3798	3789	3663	3665	3663	3669	3641	3603	3571	3537	3554	3588	3628	3669	3694	3683	3683	3675
			3833	3805	3806	3812	3780	3736	3694	3656	3651	3683	3722	3763	3784	3771	3767	3753	3686	3686	3690	3700	3670	3634	3596	3563	3537	3570	3607	3649	3666	3659	3655	3642
			>;

			PS_Config_Lmt_Open_Rawdata_N = <
				1425	1390	1366	1344	1329	1311	1293	1276	1248	1269	1282	1299	1312	1332	1359	1384	1345	1324	1300	1276	1260	1242	1225	1203	1231	1243	1255	1273	1286	1305	1333	1357
			1431	1395	1370	1348	1332	1315	1295	1282	1242	1251	1267	1284	1298	1318	1341	1369	1358	1336	1312	1288	1275	1256	1237	1224	1195	1204	1221	1237	1250	1268	1294	1317
			1443	1406	1381	1359	1345	1326	1305	1291	1282	1294	1310	1323	1341	1360	1383	1414	1375	1350	1327	1305	1291	1272	1252	1239	1241	1251	1269	1282	1300	1320	1345	1375
			1440	1405	1380	1359	1343	1326	1306	1294	1252	1263	1278	1293	1309	1330	1354	1383	1357	1333	1306	1287	1270	1255	1234	1222	1219	1230	1246	1260	1277	1296	1320	1345
			1461	1424	1397	1378	1359	1339	1321	1310	1271	1285	1296	1314	1331	1351	1375	1405	1392	1366	1339	1319	1302	1282	1265	1253	1242	1255	1269	1287	1303	1321	1345	1372
			1450	1416	1390	1370	1354	1335	1317	1303	1256	1272	1285	1302	1318	1339	1363	1390	1375	1350	1324	1303	1287	1269	1252	1237	1227	1240	1255	1272	1288	1308	1332	1358
			1464	1429	1404	1383	1366	1351	1329	1317	1276	1291	1303	1321	1337	1358	1381	1410	1392	1366	1345	1322	1305	1290	1269	1257	1233	1246	1262	1279	1295	1315	1338	1365
			1452	1416	1391	1369	1353	1336	1314	1229	1284	1297	1312	1329	1341	1361	1390	1336	1386	1358	1333	1311	1294	1278	1256	1172	1249	1258	1276	1294	1306	1326	1355	1300
			1449	1418	1392	1373	1357	1338	1320	1309	1275	1290	1306	1321	1333	1354	1377	1403	1375	1357	1331	1312	1296	1276	1260	1249	1260	1273	1294	1311	1321	1342	1366	1388
			1477	1448	1420	1398	1383	1364	1345	1333	1286	1301	1318	1329	1345	1366	1390	1415	1415	1397	1371	1348	1335	1317	1299	1287	1243	1255	1275	1287	1303	1322	1346	1369
			1461	1432	1407	1386	1371	1354	1269	1321	1311	1324	1341	1353	1371	1389	1346	1436	1396	1380	1354	1331	1317	1299	1218	1270	1278	1288	1306	1320	1335	1353	1314	1397
			1477	1447	1423	1402	1384	1368	1336	1332	1293	1306	1318	1335	1351	1371	1383	1416	1411	1393	1370	1348	1332	1317	1289	1283	1249	1260	1275	1293	1309	1329	1342	1375
			1468	1445	1417	1398	1381	1366	1346	1331	1315	1329	1342	1359	1376	1396	1421	1435	1405	1392	1366	1348	1330	1315	1297	1282	1288	1300	1316	1333	1349	1370	1393	1404
			1478	1457	1430	1410	1396	1381	1357	1345	1309	1317	1334	1352	1362	1388	1413	1425	1410	1399	1373	1350	1336	1323	1299	1289	1276	1281	1300	1318	1327	1352	1376	1384
			1485	1464	1440	1419	1404	1310	1364	1354	1333	1344	1360	1378	1390	1331	1441	1450	1416	1403	1377	1354	1339	1246	1300	1291	1306	1312	1332	1349	1359	1302	1409	1417
			1468	1447	1421	1399	1384	1369	1345	1335	1314	1327	1344	1354	1371	1390	1414	1427	1408	1397	1372	1350	1336	1321	1299	1288	1276	1286	1306	1318	1334	1354	1377	1389
			1502	1483	1455	1434	1419	1399	1378	1369	1348	1363	1381	1392	1408	1429	1452	1465	1438	1430	1402	1380	1368	1347	1329	1318	1303	1313	1334	1345	1362	1381	1404	1416
			1482	1465	1438	1418	1405	1386	1366	1350	1329	1342	1356	1372	1389	1409	1434	1444	1426	1419	1392	1370	1356	1336	1319	1302	1296	1306	1320	1338	1353	1374	1398	1408
			1522	1503	1482	1461	1363	1426	1405	1390	1350	1364	1377	1394	1329	1430	1455	1461	1447	1439	1417	1395	1299	1362	1344	1328	1313	1324	1341	1358	1293	1393	1417	1422
			1504	1486	1458	1440	1422	1406	1380	1372	1354	1362	1380	1396	1410	1431	1457	1461	1440	1431	1405	1387	1369	1353	1328	1319	1314	1320	1342	1357	1371	1393	1418	1419
			1537	1525	1498	1475	1461	1446	1419	1411	1348	1355	1373	1389	1402	1423	1448	1449	1449	1447	1421	1398	1385	1369	1346	1335	1312	1317	1338	1353	1368	1389	1413	1415
			1502	1490	1463	1361	1426	1404	1384	1375	1372	1386	1404	1336	1431	1453	1478	1477	1428	1425	1398	1295	1362	1341	1323	1312	1329	1340	1360	1295	1388	1410	1438	1437
			1520	1513	1489	1466	1451	1430	1408	1399	1372	1383	1401	1414	1428	1449	1470	1467	1454	1456	1433	1411	1396	1375	1359	1348	1333	1342	1362	1377	1390	1411	1434	1429
			1539	1531	1507	1485	1471	1451	1430	1419	1366	1377	1396	1410	1429	1444	1465	1468	1464	1467	1443	1420	1407	1386	1368	1355	1330	1339	1359	1374	1392	1406	1426	1426
			1521	1507	1500	1478	1457	1441	1419	1407	1411	1423	1440	1454	1474	1495	1501	1506	1456	1455	1446	1424	1405	1389	1372	1357	1365	1375	1395	1410	1428	1451	1458	1460
			1515	1501	1409	1473	1452	1437	1416	1404	1381	1391	1328	1428	1438	1461	1470	1465	1458	1453	1358	1423	1403	1387	1368	1355	1337	1345	1285	1384	1396	1419	1429	1423
			1542	1534	1523	1502	1485	1470	1446	1434	1427	1437	1453	1472	1486	1507	1516	1513	1459	1462	1450	1430	1415	1401	1382	1369	1379	1387	1405	1425	1438	1459	1468	1465
			1524	1516	1507	1485	1470	1453	1431	1419	1396	1406	1428	1441	1455	1476	1483	1479	1445	1447	1439	1416	1401	1386	1368	1354	1350	1357	1380	1394	1408	1430	1437	1434
			1563	1554	1546	1524	1510	1492	1468	1461	1419	1426	1449	1465	1477	1497	1501	1497	1496	1499	1493	1470	1456	1440	1420	1412	1369	1375	1400	1416	1428	1449	1456	1450
			1525	1435	1512	1489	1472	1455	1437	1425	1410	1342	1441	1455	1473	1494	1492	1494	1464	1385	1461	1438	1422	1405	1391	1377	1378	1312	1410	1425	1443	1466	1464	1466
			1572	1561	1560	1537	1521	1501	1482	1470	1421	1435	1453	1467	1483	1505	1501	1502	1512	1510	1510	1486	1470	1452	1438	1424	1378	1392	1410	1424	1441	1463	1461	1461
			1540	1527	1526	1505	1488	1470	1452	1440	1449	1459	1477	1495	1506	1528	1528	1524	1480	1480	1480	1459	1441	1424	1410	1396	1414	1422	1441	1461	1473	1494	1495	1490
			1458	1528	1529	1511	1492	1480	1458	1446	1368	1460	1477	1497	1509	1527	1524	1521	1387	1468	1471	1452	1434	1422	1403	1391	1319	1409	1426	1444	1458	1476	1475	1472
			1569	1555	1557	1539	1520	1508	1485	1477	1449	1459	1481	1494	1508	1524	1521	1518	1515	1515	1518	1500	1483	1471	1453	1444	1398	1407	1429	1443	1456	1472	1470	1466
			1560	1551	1547	1530	1518	1499	1477	1468	1476	1485	1509	1523	1536	1551	1549	1544	1490	1495	1491	1476	1464	1447	1429	1420	1435	1444	1466	1482	1495	1511	1509	1501
			1570	1562	1562	1543	1530	1512	1491	1482	1461	1474	1492	1507	1519	1533	1530	1528	1524	1528	1531	1510	1498	1480	1462	1451	1410	1422	1439	1455	1467	1481	1480	1477
			1585	1570	1571	1557	1539	1519	1503	1489	1496	1510	1529	1543	1558	1570	1566	1564	1503	1502	1504	1491	1474	1456	1441	1428	1446	1462	1479	1494	1511	1522	1519	1519
			1590	1573	1574	1562	1545	1526	1508	1494	1477	1486	1505	1518	1533	1543	1541	1536	1522	1520	1522	1510	1493	1475	1462	1447	1432	1441	1458	1475	1490	1500	1500	1494
			1595	1581	1583	1573	1555	1540	1521	1506	1510	1520	1538	1555	1569	1578	1575	1572	1537	1536	1538	1528	1509	1498	1481	1464	1459	1468	1488	1506	1519	1528	1527	1525
			1578	1563	1563	1553	1535	1521	1500	1486	1500	1508	1526	1542	1555	1562	1560	1557	1522	1521	1522	1513	1496	1483	1467	1452	1446	1456	1474	1492	1505	1513	1512	1509
			1615	1606	1600	1591	1579	1560	1539	1527	1519	1528	1549	1564	1578	1584	1581	1580	1560	1565	1561	1553	1540	1524	1504	1492	1456	1465	1486	1502	1515	1521	1521	1519
			1583	1573	1573	1562	1549	1531	1512	1501	1504	1513	1533	1547	1562	1566	1560	1560	1528	1532	1533	1521	1507	1491	1474	1464	1467	1477	1498	1513	1530	1536	1532	1533
			1640	1623	1623	1618	1600	1580	1564	1550	1516	1529	1546	1560	1575	1578	1573	1573	1570	1567	1568	1563	1544	1526	1513	1498	1463	1476	1493	1508	1524	1528	1525	1524
			1609	1592	1593	1588	1571	1553	1537	1524	1525	1537	1554	1571	1584	1585	1582	1579	1546	1543	1545	1541	1522	1504	1492	1477	1489	1503	1519	1538	1551	1553	1553	1549
			1644	1629	1629	1626	1608	1588	1573	1558	1524	1534	1552	1569	1581	1581	1578	1576	1582	1581	1582	1581	1561	1545	1531	1516	1480	1491	1509	1526	1540	1540	1538	1537
			1625	1609	1609	1608	1588	1573	1555	1542	1566	1577	1596	1612	1630	1624	1622	1624	1557	1554	1556	1554	1536	1522	1507	1494	1519	1530	1549	1564	1581	1576	1574	1574
			1624	1610	1610	1614	1597	1581	1561	1549	1562	1574	1593	1607	1621	1617	1612	1611	1549	1546	1548	1552	1536	1521	1504	1491	1516	1528	1548	1561	1576	1575	1570	1569
			1645	1630	1630	1633	1620	1601	1583	1571	1536	1550	1567	1583	1594	1590	1589	1587	1577	1575	1574	1578	1566	1548	1532	1520	1489	1504	1521	1536	1546	1542	1541	1540
			1621	1606	1606	1608	1595	1576	1560	1545	1576	1590	1606	1623	1634	1629	1627	1624	1570	1570	1570	1572	1560	1544	1530	1516	1523	1537	1555	1572	1583	1578	1578	1575
			1642	1630	1631	1633	1620	1601	1583	1567	1564	1578	1595	1612	1621	1616	1614	1608	1579	1579	1581	1585	1573	1557	1541	1527	1516	1530	1546	1564	1571	1568	1566	1561
			>;

			PS_Config_Lmt_FW_Rawdata_P = <
				1124	1108	1114	1107	1113	1111	1104	1099	1122	1111	1111	1113	1118	1121	1122	1125	1138	1134	1124	1108	1115	1117	1120	1117	1121	1124	1117	1125	1138	1124	1113	1121
			1122	1110	1113	1117	1113	1117	1113	1108	1129	1134	1134	1135	1138	1135	1108	1107	1108	1121	1122	1113	1115	1118	1120	1120	1113	1124	1117	1124	1127	1110	1108	1120
			1120	1124	1124	1122	1124	1122	1127	1138	1111	1124	1131	1131	1114	1103	1110	1120	1132	1118	1114	1128	1120	1120	1117	1121	1136	1128	1122	1128	1135	1128	1122	1115
			1111	1121	1117	1108	1103	1104	1115	1120	1128	1113	1113	1117	1117	1127	1135	1104	1115	1127	1120	1121	1111	1117	1113	1117	1122	1120	1120	1122	1117	1120	1124	1118
			1092	1135	1124	1122	1120	1121	1127	1136	1115	1115	1113	1118	1113	1121	1131	1121	1121	1115	1125	1129	1125	1122	1124	1124	1131	1136	1125	1131	1127	1125	1114	1134
			1135	1107	1108	1118	1118	1122	1120	1103	1111	1127	1127	1117	1115	1117	1117	1124	1120	1118	1124	1128	1125	1115	1118	1118	1120	1127	1129	1128	1117	1115	1107	1121
			1128	1106	1110	1107	1110	1106	1103	1110	1114	1108	1110	1108	1110	1117	1131	1117	1118	1121	1124	1114	1114	1113	1114	1111	1121	1115	1117	1113	1110	1118	1128	1104
			1135	1128	1124	1118	1124	1127	1125	1131	1111	1111	1111	1113	1121	1127	1134	1111	1143	1122	1111	1106	1113	1122	1118	1120	1114	1120	1131	1125	1122	1117	1120	1131
			1128	1113	1118	1118	1117	1113	1113	1104	1129	1125	1122	1127	1128	1114	1121	1131	1120	1121	1117	1115	1122	1121	1115	1115	1115	1124	1121	1124	1124	1124	1128	1111
			1129	1106	1107	1111	1108	1101	1103	1101	1114	1132	1128	1131	1121	1107	1117	1120	1121	1115	1121	1124	1129	1128	1127	1125	1136	1122	1120	1127	1131	1135	1113	1121
			1111	1106	1139	1139	1127	1122	1107	1107	1124	1125	1128	1129	1129	1122	1115	1110	1120	1104	1122	1122	1125	1121	1117	1113	1121	1111	1106	1113	1118	1124	1138	1111
			1118	1110	1118	1117	1120	1118	1113	1110	1135	1124	1120	1120	1120	1131	1122	1115	1107	1117	1131	1132	1125	1117	1125	1124	1124	1134	1135	1135	1125	1111	1104	1135
			1111	1124	1136	1132	1134	1132	1127	1115	1117	1124	1127	1124	1122	1125	1118	1118	1122	1110	1104	1125	1124	1129	1125	1124	1118	1120	1122	1120	1117	1125	1122	1118
			1103	1111	1127	1122	1121	1121	1111	1110	1115	1121	1122	1129	1127	1134	1120	1124	1131	1122	1110	1108	1106	1114	1114	1118	1117	1104	1106	1110	1115	1125	1136	1107
			1122	1141	1136	1127	1129	1134	1136	1141	1117	1128	1138	1129	1115	1120	1108	1108	1136	1122	1113	1113	1114	1108	1106	1108	1111	1111	1111	1114	1104	1117	1131	1128
			1113	1117	1114	1113	1115	1113	1117	1110	1124	1114	1107	1110	1115	1124	1125	1128	1117	1120	1135	1136	1134	1132	1128	1128	1128	1124	1127	1125	1134	1120	1111	1122
			1122	1127	1136	1132	1131	1132	1127	1127	1110	1118	1125	1125	1115	1106	1108	1111	1117	1113	1128	1110	1114	1115	1117	1122	1107	1106	1114	1108	1107	1117	1125	1115
			1113	1117	1122	1122	1122	1127	1127	1129	1124	1114	1110	1106	1110	1118	1121	1120	1106	1117	1118	1134	1135	1122	1134	1125	1108	1117	1118	1113	1117	1118	1128	1117
			1125	1110	1113	1115	1106	1104	1111	1111	1131	1131	1128	1125	1128	1125	1127	1125	1125	1118	1115	1110	1110	1106	1118	1135	1121	1121	1118	1117	1122	1114	1120	1120
			1115	1118	1117	1121	1113	1114	1113	1120	1127	1111	1107	1110	1111	1118	1120	1115	1128	1122	1114	1104	1104	1114	1108	1104	1132	1128	1128	1128	1122	1128	1115	1122
			1125	1135	1127	1132	1127	1125	1132	1134	1108	1132	1138	1135	1138	1125	1115	1127	1118	1118	1111	1110	1115	1114	1115	1114	1128	1122	1117	1121	1128	1122	1125	1118
			1121	1118	1118	1111	1113	1113	1121	1122	1104	1103	1104	1107	1103	1106	1115	1108	1106	1103	1107	1121	1139	1136	1139	1141	1131	1131	1128	1131	1129	1136	1111	1115
			1121	1118	1115	1118	1118	1114	1122	1120	1106	1110	1107	1114	1121	1108	1113	1118	1125	1118	1114	1106	1115	1124	1115	1120	1107	1107	1111	1104	1108	1110	1117	1128
			1127	1125	1121	1124	1118	1120	1124	1125	1115	1115	1120	1118	1118	1117	1113	1113	1118	1121	1111	1111	1120	1125	1127	1122	1129	1127	1136	1128	1122	1101	1101	1122
			1127	1122	1129	1114	1118	1117	1117	1111	1125	1128	1125	1118	1124	1124	1120	1111	1118	1115	1120	1114	1108	1113	1118	1113	1129	1131	1132	1134	1107	1111	1107	1129
			1129	1127	1132	1122	1122	1122	1121	1118	1124	1120	1125	1124	1135	1131	1128	1118	1108	1121	1118	1110	1113	1108	1110	1107	1135	1138	1134	1136	1124	1122	1121	1108
			1127	1124	1124	1122	1122	1127	1129	1131	1120	1118	1129	1122	1122	1125	1115	1115	1115	1115	1114	1108	1106	1108	1118	1114	1127	1129	1132	1117	1120	1108	1111	1118
			1120	1131	1124	1132	1128	1135	1111	1124	1138	1139	1141	1142	1141	1141	1136	1139	1128	1124	1122	1121	1110	1107	1113	1121	1113	1115	1114	1118	1118	1122	1127	1128
			1113	1111	1103	1111	1115	1115	1107	1110	1136	1134	1136	1134	1131	1127	1127	1128	1110	1110	1114	1108	1108	1113	1107	1103	1103	1103	1101	1100	1104	1107	1106	1121
			1121	1114	1113	1108	1106	1107	1120	1124	1131	1115	1129	1127	1125	1110	1125	1121	1113	1111	1107	1110	1115	1118	1113	1108	1101	1103	1117	1104	1106	1114	1113	1111
			1117	1118	1115	1108	1113	1113	1111	1118	1120	1125	1122	1125	1128	1124	1115	1114	1120	1122	1125	1115	1114	1108	1108	1117	1124	1124	1113	1115	1121	1131	1120	1141
			1124	1125	1121	1125	1127	1131	1128	1120	1114	1117	1113	1110	1110	1111	1120	1117	1106	1108	1110	1106	1107	1110	1108	1106	1127	1127	1114	1124	1124	1131	1124	1136
			1103	1110	1115	1118	1124	1125	1134	1135	1118	1108	1118	1118	1118	1120	1125	1120	1104	1110	1122	1120	1117	1111	1115	1118	1111	1111	1111	1107	1111	1108	1104	1114
			1113	1117	1117	1120	1117	1114	1121	1117	1117	1117	1120	1115	1118	1114	1103	1101	1127	1121	1110	1115	1104	1106	1108	1108	1127	1124	1124	1124	1122	1127	1113	1135
			1113	1108	1108	1111	1111	1113	1115	1128	1113	1117	1114	1113	1115	1120	1122	1127	1099	1103	1111	1111	1108	1103	1106	1117	1113	1115	1113	1114	1121	1124	1117	1128
			1118	1124	1120	1121	1117	1114	1121	1115	1120	1117	1121	1124	1124	1124	1117	1114	1111	1111	1124	1122	1121	1121	1118	1131	1125	1117	1131	1135	1145	1143	1132	1125
			1113	1115	1111	1117	1117	1115	1129	1118	1114	1117	1113	1110	1121	1114	1114	1128	1124	1122	1124	1121	1124	1118	1124	1115	1114	1114	1111	1115	1117	1117	1110	1115
			1131	1127	1134	1132	1129	1125	1128	1111	1114	1114	1108	1107	1104	1113	1121	1131	1134	1132	1125	1118	1129	1129	1115	1115	1125	1128	1125	1128	1127	1127	1114	1131
			1106	1115	1108	1106	1108	1110	1115	1121	1121	1125	1131	1128	1129	1129	1115	1115	1115	1118	1128	1136	1127	1125	1129	1127	1099	1097	1100	1097	1103	1122	1135	1111
			1124	1117	1128	1129	1127	1127	1128	1129	1115	1118	1124	1120	1120	1114	1111	1107	1121	1114	1111	1115	1115	1110	1117	1121	1128	1127	1125	1125	1128	1128	1115	1125
			1121	1122	1124	1115	1115	1117	1104	1104	1110	1115	1118	1122	1118	1110	1110	1111	1103	1114	1113	1118	1131	1127	1120	1124	1120	1124	1128	1135	1121	1121	1120	1128
			1122	1124	1120	1122	1117	1115	1114	1101	1125	1127	1117	1115	1111	1107	1097	1101	1117	1100	1096	1100	1096	1107	1106	1101	1124	1124	1122	1124	1121	1128	1115	1135
			1131	1113	1121	1122	1122	1122	1127	1134	1110	1115	1106	1122	1118	1124	1128	1128	1124	1127	1134	1142	1138	1136	1138	1143	1107	1114	1107	1114	1117	1117	1117	1121
			1125	1108	1111	1115	1118	1121	1129	1131	1101	1101	1115	1120	1139	1132	1127	1127	1125	1128	1131	1135	1135	1134	1148	1148	1122	1132	1118	1122	1124	1118	1110	1136
			1120	1114	1120	1121	1121	1122	1124	1117	1124	1124	1124	1121	1122	1120	1117	1125	1113	1115	1118	1115	1107	1110	1111	1107	1113	1115	1113	1111	1114	1121	1131	1118
			1132	1110	1113	1121	1118	1117	1127	1121	1114	1115	1114	1117	1117	1115	1131	1110	1125	1127	1127	1129	1122	1113	1122	1117	1121	1125	1118	1117	1118	1118	1114	1120
			1131	1121	1125	1129	1125	1127	1124	1134	1121	1120	1125	1128	1128	1120	1115	1121	1115	1110	1107	1110	1114	1113	1106	1110	1110	1111	1111	1111	1125	1124	1122	1114
			1132	1117	1118	1121	1128	1127	1124	1110	1099	1100	1107	1108	1122	1129	1128	1132	1108	1113	1117	1121	1121	1118	1122	1121	1108	1108	1104	1106	1111	1110	1117	1108
			1117	1128	1136	1131	1128	1129	1114	1111	1122	1115	1124	1118	1118	1125	1132	1101	1127	1128	1128	1128	1125	1125	1104	1104	1129	1136	1129	1134	1135	1134	1128	1108
			1117	1108	1108	1110	1111	1113	1113	1134	1121	1121	1127	1121	1121	1125	1124	1120	1131	1127	1120	1125	1124	1125	1131	1117	1117	1120	1115	1113	1107	1111	1114	1121
			>;

			PS_Config_Lmt_FW_Rawdata_N = <
				481	475	477	474	477	476	473	471	481	476	476	477	479	480	481	482	487	486	481	475	478	478	480	478	480	481	478	482	487	481	477	480
			481	475	477	478	477	478	477	475	484	486	486	486	487	486	475	474	475	480	481	477	478	479	480	480	477	481	478	481	483	475	475	480
			480	481	481	481	481	481	483	487	476	481	484	484	477	472	475	480	485	479	477	483	480	480	478	480	487	483	481	483	486	483	481	478
			476	480	478	475	472	473	478	480	483	477	477	478	478	483	486	473	478	483	480	480	476	478	477	478	481	480	480	481	478	480	481	479
			468	486	481	481	480	480	483	487	478	478	477	479	477	480	484	480	480	478	482	484	482	481	481	481	484	487	482	484	483	482	477	486
			486	474	475	479	479	481	480	472	476	483	483	478	478	478	478	481	480	479	481	483	482	478	479	479	480	483	484	483	478	478	474	480
			483	474	475	474	475	474	472	475	477	475	475	475	475	478	484	478	479	480	481	477	477	477	477	476	480	478	478	477	475	479	483	473
			486	483	481	479	481	483	482	484	476	476	476	477	480	483	486	476	490	481	476	474	477	481	479	480	477	480	484	482	481	478	480	484
			483	477	479	479	478	477	477	473	484	482	481	483	483	477	480	484	480	480	478	478	481	480	478	478	478	481	480	481	481	481	483	476
			484	474	474	476	475	472	472	472	477	485	483	484	480	474	478	480	480	478	480	481	484	483	483	482	487	481	480	483	484	486	477	480
			476	474	488	488	483	481	474	474	481	482	483	484	484	481	478	475	480	473	481	481	482	480	478	477	480	476	474	477	479	481	487	476
			479	475	479	478	480	479	477	475	486	481	480	480	480	484	481	478	474	478	484	485	482	478	482	481	481	486	486	486	482	476	473	486
			476	481	487	485	486	485	483	478	478	481	483	481	481	482	479	479	481	475	473	482	481	484	482	481	479	480	481	480	478	482	481	479
			472	476	483	481	480	480	476	475	478	480	481	484	483	486	480	481	484	481	475	475	474	477	477	479	478	473	474	475	478	482	487	474
			481	489	487	483	484	486	487	489	478	483	487	484	478	480	475	475	487	481	477	477	477	475	474	475	476	476	476	477	473	478	484	483
			477	478	477	477	478	477	478	475	481	477	474	475	478	481	482	483	478	480	486	487	486	485	483	483	483	481	483	482	486	480	476	481
			481	483	487	485	484	485	483	483	475	479	482	482	478	474	475	476	478	477	483	475	477	478	478	481	474	474	477	475	474	478	482	478
			477	478	481	481	481	483	483	484	481	477	475	474	475	479	480	480	474	478	479	486	486	481	486	482	475	478	479	477	478	479	483	478
			482	475	477	478	474	473	476	476	484	484	483	482	483	482	483	482	482	479	478	475	475	474	479	486	480	480	479	478	481	477	480	480
			478	479	478	480	477	477	477	480	483	476	474	475	476	479	480	478	483	481	477	473	473	477	475	473	485	483	483	483	481	483	478	481
			482	486	483	485	483	482	485	486	475	485	487	486	487	482	478	483	479	479	476	475	478	477	478	477	483	481	478	480	483	481	482	479
			480	479	479	476	477	477	480	481	473	472	473	474	472	474	478	475	474	472	474	480	488	487	488	489	484	484	483	484	484	487	476	478
			480	479	478	479	479	477	481	480	474	475	474	477	480	475	477	479	482	479	477	474	478	481	478	480	474	474	476	473	475	475	478	483
			483	482	480	481	479	480	481	482	478	478	480	479	479	478	477	477	479	480	476	476	480	482	483	481	484	483	487	483	481	472	472	481
			483	481	484	477	479	478	478	476	482	483	482	479	481	481	480	476	479	478	480	477	475	477	479	477	484	484	485	486	474	476	474	484
			484	483	485	481	481	481	480	479	481	480	482	481	486	484	483	479	475	480	479	475	477	475	475	474	486	487	486	487	481	481	480	475
			483	481	481	481	481	483	484	484	480	479	484	481	481	482	478	478	478	478	477	475	474	475	479	477	483	484	485	478	480	475	476	479
			480	484	481	485	483	486	476	481	487	488	489	489	489	489	487	488	483	481	481	480	475	474	477	480	477	478	477	479	479	481	483	483
			477	476	472	476	478	478	474	475	487	486	487	486	484	483	483	483	475	475	477	475	475	477	474	472	472	472	472	471	473	474	474	480
			480	477	477	475	474	474	480	481	484	478	484	483	482	475	482	480	477	476	474	475	478	479	477	475	472	472	478	473	474	477	477	476
			478	479	478	475	477	477	476	479	480	482	481	482	483	481	478	477	480	481	482	478	477	475	475	478	481	481	477	478	480	484	480	489
			481	482	480	482	483	484	483	480	477	478	477	475	475	476	480	478	474	475	475	474	474	475	475	474	483	483	477	481	481	484	481	487
			472	475	478	479	481	482	486	486	479	475	479	479	479	480	482	480	473	475	481	480	478	476	478	479	476	476	476	474	476	475	473	477
			477	478	478	480	478	477	480	478	478	478	480	478	479	477	472	472	483	480	475	478	473	474	475	475	483	481	481	481	481	483	477	486
			477	475	475	476	476	477	478	483	477	478	477	477	478	480	481	483	471	472	476	476	475	472	474	478	477	478	477	477	480	481	478	483
			479	481	480	480	478	477	480	478	480	478	480	481	481	481	478	477	476	476	481	481	480	480	479	484	482	478	484	486	490	490	485	482
			477	478	476	478	478	478	484	479	477	478	477	475	480	477	477	483	481	481	481	480	481	479	481	478	477	477	476	478	478	478	475	478
			484	483	486	485	484	482	483	476	477	477	475	474	473	477	480	484	486	485	482	479	484	484	478	478	482	483	482	483	483	483	477	484
			474	478	475	474	475	475	478	480	480	482	484	483	484	484	478	478	478	479	483	487	483	482	484	483	471	470	471	470	472	481	486	476
			481	478	483	484	483	483	483	484	478	479	481	480	480	477	476	474	480	477	476	478	478	475	478	480	483	483	482	482	483	483	478	482
			480	481	481	478	478	478	473	473	475	478	479	481	479	475	475	476	472	477	477	479	484	483	480	481	480	481	483	486	480	480	480	483
			481	481	480	481	478	478	477	472	482	483	478	478	476	474	470	472	478	471	469	471	469	474	474	472	481	481	481	481	480	483	478	486
			484	477	480	481	481	481	483	486	475	478	474	481	479	481	483	483	481	483	486	489	487	487	487	490	474	477	474	477	478	478	478	480
			482	475	476	478	479	480	484	484	472	472	478	480	488	485	483	483	482	483	484	486	486	486	492	492	481	485	479	481	481	479	475	487
			480	477	480	480	480	481	481	478	481	481	481	480	481	480	478	482	477	478	479	478	474	475	476	474	477	478	477	476	477	480	484	479
			485	475	477	480	479	478	483	480	477	478	477	478	478	478	484	475	482	483	483	484	481	477	481	478	480	482	479	478	479	479	477	480
			484	480	482	484	482	483	481	486	480	480	482	483	483	480	478	480	478	475	474	475	477	477	474	475	475	476	476	476	482	481	481	477
			485	478	479	480	483	483	481	475	471	471	474	475	481	484	483	485	475	477	478	480	480	479	481	480	475	475	473	474	476	475	478	475
			478	483	487	484	483	484	477	476	481	478	481	479	479	482	485	472	483	483	483	483	482	482	473	473	484	487	484	486	486	486	483	475
			478	475	475	475	476	477	477	486	480	480	483	480	480	482	481	480	484	483	480	482	481	482	484	478	478	480	478	477	474	476	477	480
			>;

			PS_Config_Lmt_FW_CC_P = <
				57	57	57	56	56	56	56	56	57	56	56	56	56	56	57	57	57	56	56	56	55	55	55	56	57	57	57	57	57	57	57	59
			59	57	57	57	57	57	57	57	56	56	56	56	56	56	56	57	57	56	56	56	56	56	56	56	56	55	55	55	56	56	56	57
			64	62	62	62	62	62	62	62	62	62	62	62	62	63	63	64	63	62	62	60	60	60	60	60	62	62	62	62	62	62	62	64
			62	62	62	62	62	62	62	62	60	60	60	60	60	60	60	62	62	60	60	60	60	60	60	60	60	60	60	60	60	60	60	62
			63	62	62	62	62	62	62	62	60	60	60	60	62	62	62	62	62	62	62	60	60	60	60	60	60	60	60	60	60	62	62	62
			63	62	62	62	62	62	62	62	62	62	62	62	62	62	62	62	62	62	62	62	60	60	60	60	62	62	62	62	62	62	62	63
			63	63	63	63	63	63	63	63	62	62	62	62	62	62	62	62	62	62	62	62	60	60	60	60	60	60	60	60	60	60	62	62
			62	60	62	60	60	60	62	62	62	62	62	62	62	62	62	62	62	60	60	60	60	60	60	60	62	62	60	62	62	62	62	62
			62	62	62	62	62	62	62	62	62	62	62	62	62	62	62	62	62	62	62	60	60	60	60	60	62	62	62	62	62	62	62	63
			63	63	63	63	63	63	63	63	62	62	62	62	62	62	62	62	63	62	62	62	62	62	62	62	60	60	60	60	60	60	62	62
			62	62	62	62	62	62	62	62	63	62	62	62	62	63	63	63	62	62	60	60	60	60	60	60	62	62	62	62	62	62	62	63
			63	63	63	63	63	63	63	63	62	62	62	62	62	62	62	62	63	62	62	62	62	62	62	62	62	60	60	60	62	62	62	62
			63	62	62	62	62	62	62	62	62	62	62	62	62	62	62	62	62	62	62	60	60	60	60	60	62	62	62	62	62	62	62	63
			63	63	63	62	63	63	63	63	62	60	60	60	62	62	62	62	62	62	62	62	62	60	62	62	60	60	60	60	60	60	62	62
			63	63	63	63	63	63	63	63	63	63	63	63	63	63	63	63	62	62	62	62	62	62	62	62	63	63	63	63	63	63	63	63
			62	62	62	62	62	62	62	62	62	60	60	60	60	62	62	62	62	62	60	60	60	60	60	60	60	60	60	60	60	60	62	62
			63	63	63	62	63	62	63	63	63	62	62	62	62	63	63	63	62	62	62	62	62	62	62	62	63	62	62	62	63	63	63	63
			63	63	63	63	63	63	63	63	63	63	63	63	63	63	63	63	63	62	62	62	62	62	62	62	63	62	62	62	62	63	63	63
			63	63	63	63	63	63	63	63	63	63	63	63	63	63	63	63	63	63	62	62	62	62	62	62	62	62	62	62	62	62	62	63
			62	62	62	62	62	62	62	62	63	63	62	63	63	63	63	63	62	62	62	62	62	62	62	62	62	62	62	62	62	62	63	63
			64	64	64	64	64	64	64	64	63	63	63	63	63	63	63	63	63	63	63	63	63	63	63	63	62	62	62	62	62	63	63	63
			63	63	63	63	63	63	63	63	63	63	63	63	63	63	63	63	62	62	62	62	62	62	62	62	63	63	63	63	63	63	63	64
			63	63	63	62	62	62	63	63	63	63	63	63	63	63	63	63	62	62	62	62	62	62	62	62	63	63	63	63	63	63	63	63
			63	63	63	63	63	63	63	63	63	63	62	62	63	63	63	63	63	63	63	63	63	63	63	63	62	62	62	62	62	63	63	63
			63	63	63	63	63	63	63	63	63	63	63	63	63	63	63	64	62	62	62	62	62	62	62	62	62	62	62	62	63	63	63	64
			63	63	63	63	63	63	63	63	63	63	62	63	63	63	63	62	63	62	62	62	62	62	62	62	62	62	62	62	62	62	62	63
			64	64	64	64	64	64	64	64	64	64	64	64	64	64	64	64	63	63	64	63	63	63	63	63	64	64	63	64	64	64	64	64
			63	63	63	63	63	63	63	63	63	63	63	63	63	63	63	63	62	62	62	62	62	62	62	62	63	63	63	63	63	63	63	63
			64	64	64	64	64	64	64	64	63	63	63	63	63	63	63	63	63	63	63	63	63	63	63	63	63	63	63	63	63	63	63	63
			64	63	64	64	64	64	64	64	64	64	64	64	64	64	64	64	63	63	63	63	63	63	63	63	64	64	63	64	64	64	64	64
			64	64	64	64	64	64	64	66	63	63	63	63	63	63	63	63	64	64	64	64	64	64	64	64	63	63	63	63	63	63	63	63
			63	63	63	63	63	63	63	63	64	64	64	64	64	64	64	64	63	63	63	63	63	63	63	63	64	64	64	64	64	64	64	64
			63	63	63	63	63	63	63	63	64	64	64	64	64	64	63	63	63	63	63	63	63	63	63	63	64	64	64	64	64	64	64	64
			64	64	64	64	64	64	64	64	63	63	63	63	63	63	63	63	64	64	64	64	64	64	64	64	63	63	63	63	63	63	63	63
			64	63	64	64	64	64	64	64	64	64	64	64	64	64	64	64	63	63	63	63	63	63	63	63	64	64	64	64	64	64	64	64
			64	64	64	64	64	64	64	64	64	64	63	63	63	63	63	63	64	64	64	64	64	64	64	64	63	63	63	63	63	63	63	63
			64	63	64	64	64	64	64	64	64	64	64	64	64	64	64	64	63	63	63	63	63	63	63	63	64	64	64	64	64	64	64	64
			64	64	64	64	64	64	64	64	64	64	63	63	63	63	63	63	63	63	63	64	63	63	64	64	63	63	63	63	63	63	63	63
			64	64	64	64	64	64	64	66	66	66	64	64	64	64	64	64	64	64	64	64	64	64	64	64	64	64	64	64	66	64	64	66
			63	63	63	63	63	63	64	64	64	64	64	64	64	63	63	63	63	63	63	63	63	63	63	63	63	64	63	64	64	63	63	64
			64	64	64	64	64	64	64	64	64	64	64	64	64	64	64	64	64	64	64	64	64	64	64	64	64	64	64	64	64	64	64	64
			64	64	64	64	64	64	64	64	64	64	64	64	64	64	64	64	64	64	64	64	64	64	64	64	64	64	64	64	64	64	64	64
			64	64	64	64	64	64	66	66	64	64	64	64	64	64	63	64	64	64	64	64	64	64	64	64	64	64	64	64	64	64	64	64
			64	64	64	64	64	64	64	64	64	64	64	64	64	64	64	64	63	63	63	63	63	63	63	63	64	64	64	64	64	64	64	64
			66	66	66	66	66	66	66	66	64	64	64	64	64	64	63	64	64	64	64	64	64	64	64	64	64	64	64	64	64	64	64	64
			64	64	64	64	64	64	64	64	66	66	66	66	64	64	64	66	63	63	64	64	64	64	64	64	64	64	64	64	64	64	64	66
			63	63	63	63	63	63	64	64	64	64	64	64	64	64	64	64	63	63	63	63	63	63	63	63	64	64	64	64	64	64	64	64
			66	64	64	64	64	64	64	66	64	64	64	64	64	64	63	64	64	64	64	64	64	64	64	64	63	64	64	64	64	63	63	66
			64	63	63	63	64	63	64	64	64	64	64	64	64	64	63	64	63	63	63	63	63	63	63	63	64	64	64	64	64	64	64	64
			63	63	63	63	63	63	63	64	63	63	62	62	62	62	62	63	63	63	63	63	63	63	63	63	62	62	62	62	62	62	62	63
			>;

			PS_Config_Lmt_FW_CC_N = <
				26	26	26	25	25	25	25	25	26	25	25	25	25	25	26	26	26	25	25	25	24	24	24	25	26	26	26	26	26	26	26	26
			26	26	26	26	26	26	26	26	25	25	25	25	25	25	25	26	26	25	25	25	25	25	25	25	25	24	24	24	25	25	25	26
			29	27	27	27	27	27	27	27	27	27	27	27	27	28	28	29	28	27	27	27	27	27	27	27	27	27	27	27	27	27	27	29
			27	27	27	27	27	27	27	27	27	27	27	27	27	27	27	27	27	27	27	27	27	27	27	27	27	27	27	27	27	27	27	27
			28	27	27	27	27	27	27	27	27	27	27	27	27	27	27	27	27	27	27	27	27	27	27	27	27	27	27	27	27	27	27	27
			28	27	27	27	27	27	27	27	27	27	27	27	27	27	27	27	27	27	27	27	27	27	27	27	27	27	27	27	27	27	27	28
			28	28	28	28	28	28	28	28	27	27	27	27	27	27	27	27	27	27	27	27	27	27	27	27	27	27	27	27	27	27	27	27
			27	27	27	27	27	27	27	27	27	27	27	27	27	27	27	27	27	27	27	27	27	27	27	27	27	27	27	27	27	27	27	27
			27	27	27	27	27	27	27	27	27	27	27	27	27	27	27	27	27	27	27	27	27	27	27	27	27	27	27	27	27	27	27	28
			28	28	28	28	28	28	28	28	27	27	27	27	27	27	27	27	28	27	27	27	27	27	27	27	27	27	27	27	27	27	27	27
			27	27	27	27	27	27	27	27	28	27	27	27	27	28	28	28	27	27	27	27	27	27	27	27	27	27	27	27	27	27	27	28
			28	28	28	28	28	28	28	28	27	27	27	27	27	27	27	27	28	27	27	27	27	27	27	27	27	27	27	27	27	27	27	27
			28	27	27	27	27	27	27	27	27	27	27	27	27	27	27	27	27	27	27	27	27	27	27	27	27	27	27	27	27	27	27	28
			28	28	28	27	28	28	28	28	27	27	27	27	27	27	27	27	27	27	27	27	27	27	27	27	27	27	27	27	27	27	27	27
			28	28	28	28	28	28	28	28	28	28	28	28	28	28	28	28	27	27	27	27	27	27	27	27	28	28	28	28	28	28	28	28
			27	27	27	27	27	27	27	27	27	27	27	27	27	27	27	27	27	27	27	27	27	27	27	27	27	27	27	27	27	27	27	27
			28	28	28	27	28	27	28	28	28	27	27	27	27	28	28	28	27	27	27	27	27	27	27	27	28	27	27	27	28	28	28	28
			28	28	28	28	28	28	28	28	28	28	28	28	28	28	28	28	28	27	27	27	27	27	27	27	28	27	27	27	27	28	28	28
			28	28	28	28	28	28	28	28	28	28	28	28	28	28	28	28	28	28	27	27	27	27	27	27	27	27	27	27	27	27	27	28
			27	27	27	27	27	27	27	27	28	28	27	28	28	28	28	28	27	27	27	27	27	27	27	27	27	27	27	27	27	27	28	28
			29	29	29	29	29	29	29	29	28	28	28	28	28	28	28	28	28	28	28	28	28	28	28	28	27	27	27	27	27	28	28	28
			28	28	28	28	28	28	28	28	28	28	28	28	28	28	28	28	27	27	27	27	27	27	27	27	28	28	28	28	28	28	28	29
			28	28	28	27	27	27	28	28	28	28	28	28	28	28	28	28	27	27	27	27	27	27	27	27	28	28	28	28	28	28	28	28
			28	28	28	28	28	28	28	28	28	28	27	27	28	28	28	28	28	28	28	28	28	28	28	28	27	27	27	27	27	28	28	28
			28	28	28	28	28	28	28	28	28	28	28	28	28	28	28	29	27	27	27	27	27	27	27	27	27	27	27	27	28	28	28	29
			28	28	28	28	28	28	28	28	28	28	27	28	28	28	28	27	28	27	27	27	27	27	27	27	27	27	27	27	27	27	27	28
			29	29	29	29	29	29	29	29	29	29	29	29	29	29	29	29	28	28	29	28	28	28	28	28	29	29	28	29	29	29	29	29
			28	28	28	28	28	28	28	28	28	28	28	28	28	28	28	28	27	27	27	27	27	27	27	27	28	28	28	28	28	28	28	28
			29	29	29	29	29	29	29	29	28	28	28	28	28	28	28	28	28	28	28	28	28	28	28	28	28	28	28	28	28	28	28	28
			29	28	29	29	29	29	29	29	29	29	29	29	29	29	29	29	28	28	28	28	28	28	28	28	29	29	28	29	29	29	29	29
			29	29	29	29	29	29	29	29	28	28	28	28	28	28	28	28	29	29	29	29	29	29	29	29	28	28	28	28	28	28	28	28
			28	28	28	28	28	28	28	28	29	29	29	29	29	29	29	29	28	28	28	28	28	28	28	28	29	29	29	29	29	29	29	29
			28	28	28	28	28	28	28	28	29	29	29	29	29	29	28	28	28	28	28	28	28	28	28	28	29	29	29	29	29	29	29	29
			29	29	29	29	29	29	29	29	28	28	28	28	28	28	28	28	29	29	29	29	29	29	29	29	28	28	28	28	28	28	28	28
			29	28	29	29	29	29	29	29	29	29	29	29	29	29	29	29	28	28	28	28	28	28	28	28	29	29	29	29	29	29	29	29
			29	29	29	29	29	29	29	29	29	29	28	28	28	28	28	28	29	29	29	29	29	29	29	29	28	28	28	28	28	28	28	28
			29	28	29	29	29	29	29	29	29	29	29	29	29	29	29	29	28	28	28	28	28	28	28	28	29	29	29	29	29	29	29	29
			29	29	29	29	29	29	29	29	29	29	28	28	28	28	28	28	28	28	28	29	28	28	29	29	28	28	28	28	28	28	28	28
			29	29	29	29	29	29	29	29	29	29	29	29	29	29	29	29	29	29	29	29	29	29	29	29	29	29	29	29	29	29	29	29
			28	28	28	28	28	28	29	29	29	29	29	29	29	28	28	28	28	28	28	28	28	28	28	28	28	29	28	29	29	28	28	29
			29	29	29	29	29	29	29	29	29	29	29	29	29	29	29	29	29	29	29	29	29	29	29	29	29	29	29	29	29	29	29	29
			29	29	29	29	29	29	29	29	29	29	29	29	29	29	29	29	29	29	29	29	29	29	29	29	29	29	29	29	29	29	29	29
			29	29	29	29	29	29	29	29	29	29	29	29	29	29	28	29	29	29	29	29	29	29	29	29	29	29	29	29	29	29	29	29
			29	29	29	29	29	29	29	29	29	29	29	29	29	29	29	29	28	28	28	28	28	28	28	28	29	29	29	29	29	29	29	29
			29	29	29	29	29	29	29	29	29	29	29	29	29	29	28	29	29	29	29	29	29	29	29	29	29	29	29	29	29	29	29	29
			29	29	29	29	29	29	29	29	29	29	29	29	29	29	29	29	28	28	29	29	29	29	29	29	29	29	29	29	29	29	29	29
			28	28	28	28	28	28	29	29	29	29	29	29	29	29	29	29	28	28	28	28	28	28	28	28	29	29	29	29	29	29	29	29
			29	29	29	29	29	29	29	29	29	29	29	29	29	29	28	29	29	29	29	29	29	29	29	29	28	29	29	29	29	28	28	29
			29	28	28	28	29	28	29	29	29	29	29	29	29	29	28	29	28	28	28	28	28	28	28	28	29	29	29	29	29	29	29	29
			28	28	28	28	28	28	28	29	28	28	27	27	27	27	27	28	28	28	28	28	28	28	28	28	27	27	27	27	27	27	27	28
			>;

			PS_Config_Lmt_FW_Diff_P = <
				50	50	50	50	50	50	50	50	50	50	50	50	50	50	50	50	50	50	50	50	50	50	50	50	50	50	50	50	50	50	50	50
				50	50	50	50	50	50	50	50	50	50	50	50	50	50	50	50	50	50	50	50	50	50	50	50	50	50	50	50	50	50	50	50
				50	50	50	50	50	50	50	50	50	50	50	50	50	50	50	50	50	50	50	50	50	50	50	50	50	50	50	50	50	50	50	50
				50	50	50	50	50	50	50	50	50	50	50	50	50	50	50	50	50	50	50	50	50	50	50	50	50	50	50	50	50	50	50	50
				50	50	50	50	50	50	50	50	50	50	50	50	50	50	50	50	50	50	50	50	50	50	50	50	50	50	50	50	50	50	50	50
				50	50	50	50	50	50	50	50	50	50	50	50	50	50	50	50	50	50	50	50	50	50	50	50	50	50	50	50	50	50	50	50
				50	50	50	50	50	50	50	50	50	50	50	50	50	50	50	50	50	50	50	50	50	50	50	50	50	50	50	50	50	50	50	50
				50	50	50	50	50	50	50	50	50	50	50	50	50	50	50	50	50	50	50	50	50	50	50	50	50	50	50	50	50	50	50	50
				50	50	50	50	50	50	50	50	50	50	50	50	50	50	50	50	50	50	50	50	50	50	50	50	50	50	50	50	50	50	50	50
				50	50	50	50	50	50	50	50	50	50	50	50	50	50	50	50	50	50	50	50	50	50	50	50	50	50	50	50	50	50	50	50
				50	50	50	50	50	50	50	50	50	50	50	50	50	50	50	50	50	50	50	50	50	50	50	50	50	50	50	50	50	50	50	50
				50	50	50	50	50	50	50	50	50	50	50	50	50	50	50	50	50	50	50	50	50	50	50	50	50	50	50	50	50	50	50	50
				50	50	50	50	50	50	50	50	50	50	50	50	50	50	50	50	50	50	50	50	50	50	50	50	50	50	50	50	50	50	50	50
				50	50	50	50	50	50	50	50	50	50	50	50	50	50	50	50	50	50	50	50	50	50	50	50	50	50	50	50	50	50	50	50
				50	50	50	50	50	50	50	50	50	50	50	50	50	50	50	50	50	50	50	50	50	50	50	50	50	50	50	50	50	50	50	50
				50	50	50	50	50	50	50	50	50	50	50	50	50	50	50	50	50	50	50	50	50	50	50	50	50	50	50	50	50	50	50	50
				50	50	50	50	50	50	50	50	50	50	50	50	50	50	50	50	50	50	50	50	50	50	50	50	50	50	50	50	50	50	50	50
				50	50	50	50	50	50	50	50	50	50	50	50	50	50	50	50	50	50	50	50	50	50	50	50	50	50	50	50	50	50	50	50
				50	50	50	50	50	50	50	50	50	50	50	50	50	50	50	50	50	50	50	50	50	50	50	50	50	50	50	50	50	50	50	50
				50	50	50	50	50	50	50	50	50	50	50	50	50	50	50	50	50	50	50	50	50	50	50	50	50	50	50	50	50	50	50	50
				50	50	50	50	50	50	50	50	50	50	50	50	50	50	50	50	50	50	50	50	50	50	50	50	50	50	50	50	50	50	50	50
				50	50	50	50	50	50	50	50	50	50	50	50	50	50	50	50	50	50	50	50	50	50	50	50	50	50	50	50	50	50	50	50
				50	50	50	50	50	50	50	50	50	50	50	50	50	50	50	50	50	50	50	50	50	50	50	50	50	50	50	50	50	50	50	50
				50	50	50	50	50	50	50	50	50	50	50	50	50	50	50	50	50	50	50	50	50	50	50	50	50	50	50	50	50	50	50	50
				50	50	50	50	50	50	50	50	50	50	50	50	50	50	50	50	50	50	50	50	50	50	50	50	50	50	50	50	50	50	50	50
				50	50	50	50	50	50	50	50	50	50	50	50	50	50	50	50	50	50	50	50	50	50	50	50	50	50	50	50	50	50	50	50
				50	50	50	50	50	50	50	50	50	50	50	50	50	50	50	50	50	50	50	50	50	50	50	50	50	50	50	50	50	50	50	50
				50	50	50	50	50	50	50	50	50	50	50	50	50	50	50	50	50	50	50	50	50	50	50	50	50	50	50	50	50	50	50	50
				50	50	50	50	50	50	50	50	50	50	50	50	50	50	50	50	50	50	50	50	50	50	50	50	50	50	50	50	50	50	50	50
				50	50	50	50	50	50	50	50	50	50	50	50	50	50	50	50	50	50	50	50	50	50	50	50	50	50	50	50	50	50	50	50
				50	50	50	50	50	50	50	50	50	50	50	50	50	50	50	50	50	50	50	50	50	50	50	50	50	50	50	50	50	50	50	50
				50	50	50	50	50	50	50	50	50	50	50	50	50	50	50	50	50	50	50	50	50	50	50	50	50	50	50	50	50	50	50	50
				50	50	50	50	50	50	50	50	50	50	50	50	50	50	50	50	50	50	50	50	50	50	50	50	50	50	50	50	50	50	50	50
				50	50	50	50	50	50	50	50	50	50	50	50	50	50	50	50	50	50	50	50	50	50	50	50	50	50	50	50	50	50	50	50
				50	50	50	50	50	50	50	50	50	50	50	50	50	50	50	50	50	50	50	50	50	50	50	50	50	50	50	50	50	50	50	50
				50	50	50	50	50	50	50	50	50	50	50	50	50	50	50	50	50	50	50	50	50	50	50	50	50	50	50	50	50	50	50	50
				50	50	50	50	50	50	50	50	50	50	50	50	50	50	50	50	50	50	50	50	50	50	50	50	50	50	50	50	50	50	50	50
				50	50	50	50	50	50	50	50	50	50	50	50	50	50	50	50	50	50	50	50	50	50	50	50	50	50	50	50	50	50	50	50
				50	50	50	50	50	50	50	50	50	50	50	50	50	50	50	50	50	50	50	50	50	50	50	50	50	50	50	50	50	50	50	50
				50	50	50	50	50	50	50	50	50	50	50	50	50	50	50	50	50	50	50	50	50	50	50	50	50	50	50	50	50	50	50	50
				50	50	50	50	50	50	50	50	50	50	50	50	50	50	50	50	50	50	50	50	50	50	50	50	50	50	50	50	50	50	50	50
				50	50	50	50	50	50	50	50	50	50	50	50	50	50	50	50	50	50	50	50	50	50	50	50	50	50	50	50	50	50	50	50
				50	50	50	50	50	50	50	50	50	50	50	50	50	50	50	50	50	50	50	50	50	50	50	50	50	50	50	50	50	50	50	50
				50	50	50	50	50	50	50	50	50	50	50	50	50	50	50	50	50	50	50	50	50	50	50	50	50	50	50	50	50	50	50	50
				50	50	50	50	50	50	50	50	50	50	50	50	50	50	50	50	50	50	50	50	50	50	50	50	50	50	50	50	50	50	50	50
				50	50	50	50	50	50	50	50	50	50	50	50	50	50	50	50	50	50	50	50	50	50	50	50	50	50	50	50	50	50	50	50
				50	50	50	50	50	50	50	50	50	50	50	50	50	50	50	50	50	50	50	50	50	50	50	50	50	50	50	50	50	50	50	50
				50	50	50	50	50	50	50	50	50	50	50	50	50	50	50	50	50	50	50	50	50	50	50	50	50	50	50	50	50	50	50	50
				50	50	50	50	50	50	50	50	50	50	50	50	50	50	50	50	50	50	50	50	50	50	50	50	50	50	50	50	50	50	50	50
				50	50	50	50	50	50	50	50	50	50	50	50	50	50	50	50	50	50	50	50	50	50	50	50	50	50	50	50	50	50	50	50
				75	75	75>;

			PS_Config_Lmt_FW_Diff_N = <
				(-50)	(-50)	(-50)	(-50)	(-50)	(-50)	(-50)	(-50)	(-50)	(-50)	(-50)	(-50)	(-50)	(-50)	(-50)	(-50)	(-50)	(-50)	(-50)	(-50)	(-50)	(-50)	(-50)	(-50)	(-50)	(-50)	(-50)	(-50)	(-50)	(-50)	(-50)	(-50)
				(-50)	(-50)	(-50)	(-50)	(-50)	(-50)	(-50)	(-50)	(-50)	(-50)	(-50)	(-50)	(-50)	(-50)	(-50)	(-50)	(-50)	(-50)	(-50)	(-50)	(-50)	(-50)	(-50)	(-50)	(-50)	(-50)	(-50)	(-50)	(-50)	(-50)	(-50)	(-50)
				(-50)	(-50)	(-50)	(-50)	(-50)	(-50)	(-50)	(-50)	(-50)	(-50)	(-50)	(-50)	(-50)	(-50)	(-50)	(-50)	(-50)	(-50)	(-50)	(-50)	(-50)	(-50)	(-50)	(-50)	(-50)	(-50)	(-50)	(-50)	(-50)	(-50)	(-50)	(-50)
				(-50)	(-50)	(-50)	(-50)	(-50)	(-50)	(-50)	(-50)	(-50)	(-50)	(-50)	(-50)	(-50)	(-50)	(-50)	(-50)	(-50)	(-50)	(-50)	(-50)	(-50)	(-50)	(-50)	(-50)	(-50)	(-50)	(-50)	(-50)	(-50)	(-50)	(-50)	(-50)
				(-50)	(-50)	(-50)	(-50)	(-50)	(-50)	(-50)	(-50)	(-50)	(-50)	(-50)	(-50)	(-50)	(-50)	(-50)	(-50)	(-50)	(-50)	(-50)	(-50)	(-50)	(-50)	(-50)	(-50)	(-50)	(-50)	(-50)	(-50)	(-50)	(-50)	(-50)	(-50)
				(-50)	(-50)	(-50)	(-50)	(-50)	(-50)	(-50)	(-50)	(-50)	(-50)	(-50)	(-50)	(-50)	(-50)	(-50)	(-50)	(-50)	(-50)	(-50)	(-50)	(-50)	(-50)	(-50)	(-50)	(-50)	(-50)	(-50)	(-50)	(-50)	(-50)	(-50)	(-50)
				(-50)	(-50)	(-50)	(-50)	(-50)	(-50)	(-50)	(-50)	(-50)	(-50)	(-50)	(-50)	(-50)	(-50)	(-50)	(-50)	(-50)	(-50)	(-50)	(-50)	(-50)	(-50)	(-50)	(-50)	(-50)	(-50)	(-50)	(-50)	(-50)	(-50)	(-50)	(-50)
				(-50)	(-50)	(-50)	(-50)	(-50)	(-50)	(-50)	(-50)	(-50)	(-50)	(-50)	(-50)	(-50)	(-50)	(-50)	(-50)	(-50)	(-50)	(-50)	(-50)	(-50)	(-50)	(-50)	(-50)	(-50)	(-50)	(-50)	(-50)	(-50)	(-50)	(-50)	(-50)
				(-50)	(-50)	(-50)	(-50)	(-50)	(-50)	(-50)	(-50)	(-50)	(-50)	(-50)	(-50)	(-50)	(-50)	(-50)	(-50)	(-50)	(-50)	(-50)	(-50)	(-50)	(-50)	(-50)	(-50)	(-50)	(-50)	(-50)	(-50)	(-50)	(-50)	(-50)	(-50)
				(-50)	(-50)	(-50)	(-50)	(-50)	(-50)	(-50)	(-50)	(-50)	(-50)	(-50)	(-50)	(-50)	(-50)	(-50)	(-50)	(-50)	(-50)	(-50)	(-50)	(-50)	(-50)	(-50)	(-50)	(-50)	(-50)	(-50)	(-50)	(-50)	(-50)	(-50)	(-50)
				(-50)	(-50)	(-50)	(-50)	(-50)	(-50)	(-50)	(-50)	(-50)	(-50)	(-50)	(-50)	(-50)	(-50)	(-50)	(-50)	(-50)	(-50)	(-50)	(-50)	(-50)	(-50)	(-50)	(-50)	(-50)	(-50)	(-50)	(-50)	(-50)	(-50)	(-50)	(-50)
				(-50)	(-50)	(-50)	(-50)	(-50)	(-50)	(-50)	(-50)	(-50)	(-50)	(-50)	(-50)	(-50)	(-50)	(-50)	(-50)	(-50)	(-50)	(-50)	(-50)	(-50)	(-50)	(-50)	(-50)	(-50)	(-50)	(-50)	(-50)	(-50)	(-50)	(-50)	(-50)
				(-50)	(-50)	(-50)	(-50)	(-50)	(-50)	(-50)	(-50)	(-50)	(-50)	(-50)	(-50)	(-50)	(-50)	(-50)	(-50)	(-50)	(-50)	(-50)	(-50)	(-50)	(-50)	(-50)	(-50)	(-50)	(-50)	(-50)	(-50)	(-50)	(-50)	(-50)	(-50)
				(-50)	(-50)	(-50)	(-50)	(-50)	(-50)	(-50)	(-50)	(-50)	(-50)	(-50)	(-50)	(-50)	(-50)	(-50)	(-50)	(-50)	(-50)	(-50)	(-50)	(-50)	(-50)	(-50)	(-50)	(-50)	(-50)	(-50)	(-50)	(-50)	(-50)	(-50)	(-50)
				(-50)	(-50)	(-50)	(-50)	(-50)	(-50)	(-50)	(-50)	(-50)	(-50)	(-50)	(-50)	(-50)	(-50)	(-50)	(-50)	(-50)	(-50)	(-50)	(-50)	(-50)	(-50)	(-50)	(-50)	(-50)	(-50)	(-50)	(-50)	(-50)	(-50)	(-50)	(-50)
				(-50)	(-50)	(-50)	(-50)	(-50)	(-50)	(-50)	(-50)	(-50)	(-50)	(-50)	(-50)	(-50)	(-50)	(-50)	(-50)	(-50)	(-50)	(-50)	(-50)	(-50)	(-50)	(-50)	(-50)	(-50)	(-50)	(-50)	(-50)	(-50)	(-50)	(-50)	(-50)
				(-50)	(-50)	(-50)	(-50)	(-50)	(-50)	(-50)	(-50)	(-50)	(-50)	(-50)	(-50)	(-50)	(-50)	(-50)	(-50)	(-50)	(-50)	(-50)	(-50)	(-50)	(-50)	(-50)	(-50)	(-50)	(-50)	(-50)	(-50)	(-50)	(-50)	(-50)	(-50)
				(-50)	(-50)	(-50)	(-50)	(-50)	(-50)	(-50)	(-50)	(-50)	(-50)	(-50)	(-50)	(-50)	(-50)	(-50)	(-50)	(-50)	(-50)	(-50)	(-50)	(-50)	(-50)	(-50)	(-50)	(-50)	(-50)	(-50)	(-50)	(-50)	(-50)	(-50)	(-50)
				(-50)	(-50)	(-50)	(-50)	(-50)	(-50)	(-50)	(-50)	(-50)	(-50)	(-50)	(-50)	(-50)	(-50)	(-50)	(-50)	(-50)	(-50)	(-50)	(-50)	(-50)	(-50)	(-50)	(-50)	(-50)	(-50)	(-50)	(-50)	(-50)	(-50)	(-50)	(-50)
				(-50)	(-50)	(-50)	(-50)	(-50)	(-50)	(-50)	(-50)	(-50)	(-50)	(-50)	(-50)	(-50)	(-50)	(-50)	(-50)	(-50)	(-50)	(-50)	(-50)	(-50)	(-50)	(-50)	(-50)	(-50)	(-50)	(-50)	(-50)	(-50)	(-50)	(-50)	(-50)
				(-50)	(-50)	(-50)	(-50)	(-50)	(-50)	(-50)	(-50)	(-50)	(-50)	(-50)	(-50)	(-50)	(-50)	(-50)	(-50)	(-50)	(-50)	(-50)	(-50)	(-50)	(-50)	(-50)	(-50)	(-50)	(-50)	(-50)	(-50)	(-50)	(-50)	(-50)	(-50)
				(-50)	(-50)	(-50)	(-50)	(-50)	(-50)	(-50)	(-50)	(-50)	(-50)	(-50)	(-50)	(-50)	(-50)	(-50)	(-50)	(-50)	(-50)	(-50)	(-50)	(-50)	(-50)	(-50)	(-50)	(-50)	(-50)	(-50)	(-50)	(-50)	(-50)	(-50)	(-50)
				(-50)	(-50)	(-50)	(-50)	(-50)	(-50)	(-50)	(-50)	(-50)	(-50)	(-50)	(-50)	(-50)	(-50)	(-50)	(-50)	(-50)	(-50)	(-50)	(-50)	(-50)	(-50)	(-50)	(-50)	(-50)	(-50)	(-50)	(-50)	(-50)	(-50)	(-50)	(-50)
				(-50)	(-50)	(-50)	(-50)	(-50)	(-50)	(-50)	(-50)	(-50)	(-50)	(-50)	(-50)	(-50)	(-50)	(-50)	(-50)	(-50)	(-50)	(-50)	(-50)	(-50)	(-50)	(-50)	(-50)	(-50)	(-50)	(-50)	(-50)	(-50)	(-50)	(-50)	(-50)
				(-50)	(-50)	(-50)	(-50)	(-50)	(-50)	(-50)	(-50)	(-50)	(-50)	(-50)	(-50)	(-50)	(-50)	(-50)	(-50)	(-50)	(-50)	(-50)	(-50)	(-50)	(-50)	(-50)	(-50)	(-50)	(-50)	(-50)	(-50)	(-50)	(-50)	(-50)	(-50)
				(-50)	(-50)	(-50)	(-50)	(-50)	(-50)	(-50)	(-50)	(-50)	(-50)	(-50)	(-50)	(-50)	(-50)	(-50)	(-50)	(-50)	(-50)	(-50)	(-50)	(-50)	(-50)	(-50)	(-50)	(-50)	(-50)	(-50)	(-50)	(-50)	(-50)	(-50)	(-50)
				(-50)	(-50)	(-50)	(-50)	(-50)	(-50)	(-50)	(-50)	(-50)	(-50)	(-50)	(-50)	(-50)	(-50)	(-50)	(-50)	(-50)	(-50)	(-50)	(-50)	(-50)	(-50)	(-50)	(-50)	(-50)	(-50)	(-50)	(-50)	(-50)	(-50)	(-50)	(-50)
				(-50)	(-50)	(-50)	(-50)	(-50)	(-50)	(-50)	(-50)	(-50)	(-50)	(-50)	(-50)	(-50)	(-50)	(-50)	(-50)	(-50)	(-50)	(-50)	(-50)	(-50)	(-50)	(-50)	(-50)	(-50)	(-50)	(-50)	(-50)	(-50)	(-50)	(-50)	(-50)
				(-50)	(-50)	(-50)	(-50)	(-50)	(-50)	(-50)	(-50)	(-50)	(-50)	(-50)	(-50)	(-50)	(-50)	(-50)	(-50)	(-50)	(-50)	(-50)	(-50)	(-50)	(-50)	(-50)	(-50)	(-50)	(-50)	(-50)	(-50)	(-50)	(-50)	(-50)	(-50)
				(-50)	(-50)	(-50)	(-50)	(-50)	(-50)	(-50)	(-50)	(-50)	(-50)	(-50)	(-50)	(-50)	(-50)	(-50)	(-50)	(-50)	(-50)	(-50)	(-50)	(-50)	(-50)	(-50)	(-50)	(-50)	(-50)	(-50)	(-50)	(-50)	(-50)	(-50)	(-50)
				(-50)	(-50)	(-50)	(-50)	(-50)	(-50)	(-50)	(-50)	(-50)	(-50)	(-50)	(-50)	(-50)	(-50)	(-50)	(-50)	(-50)	(-50)	(-50)	(-50)	(-50)	(-50)	(-50)	(-50)	(-50)	(-50)	(-50)	(-50)	(-50)	(-50)	(-50)	(-50)
				(-50)	(-50)	(-50)	(-50)	(-50)	(-50)	(-50)	(-50)	(-50)	(-50)	(-50)	(-50)	(-50)	(-50)	(-50)	(-50)	(-50)	(-50)	(-50)	(-50)	(-50)	(-50)	(-50)	(-50)	(-50)	(-50)	(-50)	(-50)	(-50)	(-50)	(-50)	(-50)
				(-50)	(-50)	(-50)	(-50)	(-50)	(-50)	(-50)	(-50)	(-50)	(-50)	(-50)	(-50)	(-50)	(-50)	(-50)	(-50)	(-50)	(-50)	(-50)	(-50)	(-50)	(-50)	(-50)	(-50)	(-50)	(-50)	(-50)	(-50)	(-50)	(-50)	(-50)	(-50)
				(-50)	(-50)	(-50)	(-50)	(-50)	(-50)	(-50)	(-50)	(-50)	(-50)	(-50)	(-50)	(-50)	(-50)	(-50)	(-50)	(-50)	(-50)	(-50)	(-50)	(-50)	(-50)	(-50)	(-50)	(-50)	(-50)	(-50)	(-50)	(-50)	(-50)	(-50)	(-50)
				(-50)	(-50)	(-50)	(-50)	(-50)	(-50)	(-50)	(-50)	(-50)	(-50)	(-50)	(-50)	(-50)	(-50)	(-50)	(-50)	(-50)	(-50)	(-50)	(-50)	(-50)	(-50)	(-50)	(-50)	(-50)	(-50)	(-50)	(-50)	(-50)	(-50)	(-50)	(-50)
				(-50)	(-50)	(-50)	(-50)	(-50)	(-50)	(-50)	(-50)	(-50)	(-50)	(-50)	(-50)	(-50)	(-50)	(-50)	(-50)	(-50)	(-50)	(-50)	(-50)	(-50)	(-50)	(-50)	(-50)	(-50)	(-50)	(-50)	(-50)	(-50)	(-50)	(-50)	(-50)
				(-50)	(-50)	(-50)	(-50)	(-50)	(-50)	(-50)	(-50)	(-50)	(-50)	(-50)	(-50)	(-50)	(-50)	(-50)	(-50)	(-50)	(-50)	(-50)	(-50)	(-50)	(-50)	(-50)	(-50)	(-50)	(-50)	(-50)	(-50)	(-50)	(-50)	(-50)	(-50)
				(-50)	(-50)	(-50)	(-50)	(-50)	(-50)	(-50)	(-50)	(-50)	(-50)	(-50)	(-50)	(-50)	(-50)	(-50)	(-50)	(-50)	(-50)	(-50)	(-50)	(-50)	(-50)	(-50)	(-50)	(-50)	(-50)	(-50)	(-50)	(-50)	(-50)	(-50)	(-50)
				(-50)	(-50)	(-50)	(-50)	(-50)	(-50)	(-50)	(-50)	(-50)	(-50)	(-50)	(-50)	(-50)	(-50)	(-50)	(-50)	(-50)	(-50)	(-50)	(-50)	(-50)	(-50)	(-50)	(-50)	(-50)	(-50)	(-50)	(-50)	(-50)	(-50)	(-50)	(-50)
				(-50)	(-50)	(-50)	(-50)	(-50)	(-50)	(-50)	(-50)	(-50)	(-50)	(-50)	(-50)	(-50)	(-50)	(-50)	(-50)	(-50)	(-50)	(-50)	(-50)	(-50)	(-50)	(-50)	(-50)	(-50)	(-50)	(-50)	(-50)	(-50)	(-50)	(-50)	(-50)
				(-50)	(-50)	(-50)	(-50)	(-50)	(-50)	(-50)	(-50)	(-50)	(-50)	(-50)	(-50)	(-50)	(-50)	(-50)	(-50)	(-50)	(-50)	(-50)	(-50)	(-50)	(-50)	(-50)	(-50)	(-50)	(-50)	(-50)	(-50)	(-50)	(-50)	(-50)	(-50)
				(-50)	(-50)	(-50)	(-50)	(-50)	(-50)	(-50)	(-50)	(-50)	(-50)	(-50)	(-50)	(-50)	(-50)	(-50)	(-50)	(-50)	(-50)	(-50)	(-50)	(-50)	(-50)	(-50)	(-50)	(-50)	(-50)	(-50)	(-50)	(-50)	(-50)	(-50)	(-50)
				(-50)	(-50)	(-50)	(-50)	(-50)	(-50)	(-50)	(-50)	(-50)	(-50)	(-50)	(-50)	(-50)	(-50)	(-50)	(-50)	(-50)	(-50)	(-50)	(-50)	(-50)	(-50)	(-50)	(-50)	(-50)	(-50)	(-50)	(-50)	(-50)	(-50)	(-50)	(-50)
				(-50)	(-50)	(-50)	(-50)	(-50)	(-50)	(-50)	(-50)	(-50)	(-50)	(-50)	(-50)	(-50)	(-50)	(-50)	(-50)	(-50)	(-50)	(-50)	(-50)	(-50)	(-50)	(-50)	(-50)	(-50)	(-50)	(-50)	(-50)	(-50)	(-50)	(-50)	(-50)
				(-50)	(-50)	(-50)	(-50)	(-50)	(-50)	(-50)	(-50)	(-50)	(-50)	(-50)	(-50)	(-50)	(-50)	(-50)	(-50)	(-50)	(-50)	(-50)	(-50)	(-50)	(-50)	(-50)	(-50)	(-50)	(-50)	(-50)	(-50)	(-50)	(-50)	(-50)	(-50)
				(-50)	(-50)	(-50)	(-50)	(-50)	(-50)	(-50)	(-50)	(-50)	(-50)	(-50)	(-50)	(-50)	(-50)	(-50)	(-50)	(-50)	(-50)	(-50)	(-50)	(-50)	(-50)	(-50)	(-50)	(-50)	(-50)	(-50)	(-50)	(-50)	(-50)	(-50)	(-50)
				(-50)	(-50)	(-50)	(-50)	(-50)	(-50)	(-50)	(-50)	(-50)	(-50)	(-50)	(-50)	(-50)	(-50)	(-50)	(-50)	(-50)	(-50)	(-50)	(-50)	(-50)	(-50)	(-50)	(-50)	(-50)	(-50)	(-50)	(-50)	(-50)	(-50)	(-50)	(-50)
				(-50)	(-50)	(-50)	(-50)	(-50)	(-50)	(-50)	(-50)	(-50)	(-50)	(-50)	(-50)	(-50)	(-50)	(-50)	(-50)	(-50)	(-50)	(-50)	(-50)	(-50)	(-50)	(-50)	(-50)	(-50)	(-50)	(-50)	(-50)	(-50)	(-50)	(-50)	(-50)
				(-50)	(-50)	(-50)	(-50)	(-50)	(-50)	(-50)	(-50)	(-50)	(-50)	(-50)	(-50)	(-50)	(-50)	(-50)	(-50)	(-50)	(-50)	(-50)	(-50)	(-50)	(-50)	(-50)	(-50)	(-50)	(-50)	(-50)	(-50)	(-50)	(-50)	(-50)	(-50)
				(-50)	(-50)	(-50)	(-50)	(-50)	(-50)	(-50)	(-50)	(-50)	(-50)	(-50)	(-50)	(-50)	(-50)	(-50)	(-50)	(-50)	(-50)	(-50)	(-50)	(-50)	(-50)	(-50)	(-50)	(-50)	(-50)	(-50)	(-50)	(-50)	(-50)	(-50)	(-50)
				(-75)	(-75)	(-75)>;

			PS_Config_Lmt_PenTipX_FW_Raw_P = <
				600	600	600	600	600	600	600	600	600	600	600	600	600	600	600	600	600	600	600	600	600	600	600	600	600	600	600	600	600	600	600	600
				600	600	600	600	600	600	600	600	600	600	600	600	600	600	600	600	600	600	600	600	600	600	600	600	600	600	600	600	600	600	600	600
				600	600	600	600	600	600	600	600	600	600	600	600	600	600	600	600	600	600	600	600	600	600	600	600	600	600	600	600	600	600	600	600
				600	600	600	600	600	600	600	600	600	600	600	600	600	600	600	600	600	600	600	600	600	600	600	600	600	600	600	600	600	600	600	600
				600	600	600	600	600	600	600	600	600	600	600	600	600	600	600	600	600	600	600	600	600	600	600	600	600	600	600	600	600	600	600	600
				600	600	600	600	600	600	600	600	600	600	600	600	600	600	600	600	600	600	600	600	600	600	600	600	600	600	600	600	600	600	600	600>;

			PS_Config_Lmt_PenTipX_FW_Raw_N = <
				0	0	0	0	0	0	0	0	0	0	0	0	0	0	0	0	0	0	0	0	0	0	0	0	0	0	0	0	0	0	0	0
				0	0	0	0	0	0	0	0	0	0	0	0	0	0	0	0	0	0	0	0	0	0	0	0	0	0	0	0	0	0	0	0
				0	0	0	0	0	0	0	0	0	0	0	0	0	0	0	0	0	0	0	0	0	0	0	0	0	0	0	0	0	0	0	0
				0	0	0	0	0	0	0	0	0	0	0	0	0	0	0	0	0	0	0	0	0	0	0	0	0	0	0	0	0	0	0	0
				0	0	0	0	0	0	0	0	0	0	0	0	0	0	0	0	0	0	0	0	0	0	0	0	0	0	0	0	0	0	0	0
				0	0	0	0	0	0	0	0	0	0	0	0	0	0	0	0	0	0	0	0	0	0	0	0	0	0	0	0	0	0	0	0>;

			PS_Config_Lmt_PenTipY_FW_Raw_P = <
				600	600	600	600
				600	600	600	600
				600	600	600	600
				600	600	600	600
				600	600	600	600
				600	600	600	600
				600	600	600	600
				600	600	600	600
				600	600	600	600
				600	600	600	600
				600	600	600	600
				600	600	600	600
				600	600	600	600
				600	600	600	600
				600	600	600	600
				600	600	600	600
				600	600	600	600
				600	600	600	600
				600	600	600	600
				600	600	600	600
				600	600	600	600
				600	600	600	600
				600	600	600	600
				600	600	600	600
				600	600	600	600
				600	600	600	600
				600	600	600	600
				600	600	600	600
				600	600	600	600
				600	600	600	600
				600	600	600	600
				600	600	600	600
				600	600	600	600
				600	600	600	600
				600	600	600	600
				600	600	600	600
				600	600	600	600
				600	600	600	600
				600	600	600	600
				600	600	600	600
				600	600	600	600
				600	600	600	600
				600	600	600	600
				600	600	600	600
				600	600	600	600
				600	600	600	600
				600	600	600	600
				600	600	600	600
				600	600	600	600
				600	600	600	600>;

			PS_Config_Lmt_PenTipY_FW_Raw_N = <
				0	0	0	0
				0	0	0	0
				0	0	0	0
				0	0	0	0
				0	0	0	0
				0	0	0	0
				0	0	0	0
				0	0	0	0
				0	0	0	0
				0	0	0	0
				0	0	0	0
				0	0	0	0
				0	0	0	0
				0	0	0	0
				0	0	0	0
				0	0	0	0
				0	0	0	0
				0	0	0	0
				0	0	0	0
				0	0	0	0
				0	0	0	0
				0	0	0	0
				0	0	0	0
				0	0	0	0
				0	0	0	0
				0	0	0	0
				0	0	0	0
				0	0	0	0
				0	0	0	0
				0	0	0	0
				0	0	0	0
				0	0	0	0
				0	0	0	0
				0	0	0	0
				0	0	0	0
				0	0	0	0
				0	0	0	0
				0	0	0	0
				0	0	0	0
				0	0	0	0
				0	0	0	0
				0	0	0	0
				0	0	0	0
				0	0	0	0
				0	0	0	0
				0	0	0	0
				0	0	0	0
				0	0	0	0
				0	0	0	0
				0	0	0	0>;

			PS_Config_Lmt_PenRingX_FW_Raw_P = <
				600	600	600	600	600	600	600	600	600	600	600	600	600	600	600	600	600	600	600	600	600	600	600	600	600	600	600	600	600	600	600	600
				600	600	600	600	600	600	600	600	600	600	600	600	600	600	600	600	600	600	600	600	600	600	600	600	600	600	600	600	600	600	600	600
				600	600	600	600	600	600	600	600	600	600	600	600	600	600	600	600	600	600	600	600	600	600	600	600	600	600	600	600	600	600	600	600
				600	600	600	600	600	600	600	600	600	600	600	600	600	600	600	600	600	600	600	600	600	600	600	600	600	600	600	600	600	600	600	600
				600	600	600	600	600	600	600	600	600	600	600	600	600	600	600	600	600	600	600	600	600	600	600	600	600	600	600	600	600	600	600	600
				600	600	600	600	600	600	600	600	600	600	600	600	600	600	600	600	600	600	600	600	600	600	600	600	600	600	600	600	600	600	600	600>;

			PS_Config_Lmt_PenRingX_FW_Raw_N = <
				0	0	0	0	0	0	0	0	0	0	0	0	0	0	0	0	0	0	0	0	0	0	0	0	0	0	0	0	0	0	0	0
				0	0	0	0	0	0	0	0	0	0	0	0	0	0	0	0	0	0	0	0	0	0	0	0	0	0	0	0	0	0	0	0
				0	0	0	0	0	0	0	0	0	0	0	0	0	0	0	0	0	0	0	0	0	0	0	0	0	0	0	0	0	0	0	0
				0	0	0	0	0	0	0	0	0	0	0	0	0	0	0	0	0	0	0	0	0	0	0	0	0	0	0	0	0	0	0	0
				0	0	0	0	0	0	0	0	0	0	0	0	0	0	0	0	0	0	0	0	0	0	0	0	0	0	0	0	0	0	0	0
				0	0	0	0	0	0	0	0	0	0	0	0	0	0	0	0	0	0	0	0	0	0	0	0	0	0	0	0	0	0	0	0>;

			PS_Config_Lmt_PenRingY_FW_Raw_P = <
				600	600	600	600
				600	600	600	600
				600	600	600	600
				600	600	600	600
				600	600	600	600
				600	600	600	600
				600	600	600	600
				600	600	600	600
				600	600	600	600
				600	600	600	600
				600	600	600	600
				600	600	600	600
				600	600	600	600
				600	600	600	600
				600	600	600	600
				600	600	600	600
				600	600	600	600
				600	600	600	600
				600	600	600	600
				600	600	600	600
				600	600	600	600
				600	600	600	600
				600	600	600	600
				600	600	600	600
				600	600	600	600
				600	600	600	600
				600	600	600	600
				600	600	600	600
				600	600	600	600
				600	600	600	600
				600	600	600	600
				600	600	600	600
				600	600	600	600
				600	600	600	600
				600	600	600	600
				600	600	600	600
				600	600	600	600
				600	600	600	600
				600	600	600	600
				600	600	600	600
				600	600	600	600
				600	600	600	600
				600	600	600	600
				600	600	600	600
				600	600	600	600
				600	600	600	600
				600	600	600	600
				600	600	600	600
				600	600	600	600
				600	600	600	600>;

			PS_Config_Lmt_PenRingY_FW_Raw_N = <
				0	0	0	0
				0	0	0	0
				0	0	0	0
				0	0	0	0
				0	0	0	0
				0	0	0	0
				0	0	0	0
				0	0	0	0
				0	0	0	0
				0	0	0	0
				0	0	0	0
				0	0	0	0
				0	0	0	0
				0	0	0	0
				0	0	0	0
				0	0	0	0
				0	0	0	0
				0	0	0	0
				0	0	0	0
				0	0	0	0
				0	0	0	0
				0	0	0	0
				0	0	0	0
				0	0	0	0
				0	0	0	0
				0	0	0	0
				0	0	0	0
				0	0	0	0
				0	0	0	0
				0	0	0	0
				0	0	0	0
				0	0	0	0
				0	0	0	0
				0	0	0	0
				0	0	0	0
				0	0	0	0
				0	0	0	0
				0	0	0	0
				0	0	0	0
				0	0	0	0
				0	0	0	0
				0	0	0	0
				0	0	0	0
				0	0	0	0
				0	0	0	0
				0	0	0	0
				0	0	0	0
				0	0	0	0
				0	0	0	0
				0	0	0	0>;

			PS_Config_Lmt_PenTipX_FW_Diff_P = <
				600	600	600	600	600	600	600	600	600	600	600	600	600	600	600	600	600	600	600	600	600	600	600	600	600	600	600	600	600	600	600	600
				600	600	600	600	600	600	600	600	600	600	600	600	600	600	600	600	600	600	600	600	600	600	600	600	600	600	600	600	600	600	600	600
				600	600	600	600	600	600	600	600	600	600	600	600	600	600	600	600	600	600	600	600	600	600	600	600	600	600	600	600	600	600	600	600
				600	600	600	600	600	600	600	600	600	600	600	600	600	600	600	600	600	600	600	600	600	600	600	600	600	600	600	600	600	600	600	600
				600	600	600	600	600	600	600	600	600	600	600	600	600	600	600	600	600	600	600	600	600	600	600	600	600	600	600	600	600	600	600	600
				600	600	600	600	600	600	600	600	600	600	600	600	600	600	600	600	600	600	600	600	600	600	600	600	600	600	600	600	600	600	600	600>;

			PS_Config_Lmt_PenTipX_FW_Diff_N = <
				(-600)	(-600)	(-600)	(-600)	(-600)	(-600)	(-600)	(-600)	(-600)	(-600)	(-600)	(-600)	(-600)	(-600)	(-600)	(-600)	(-600)	(-600)	(-600)	(-600)	(-600)	(-600)	(-600)	(-600)	(-600)	(-600)	(-600)	(-600)	(-600)	(-600)	(-600)	(-600)
				(-600)	(-600)	(-600)	(-600)	(-600)	(-600)	(-600)	(-600)	(-600)	(-600)	(-600)	(-600)	(-600)	(-600)	(-600)	(-600)	(-600)	(-600)	(-600)	(-600)	(-600)	(-600)	(-600)	(-600)	(-600)	(-600)	(-600)	(-600)	(-600)	(-600)	(-600)	(-600)
				(-600)	(-600)	(-600)	(-600)	(-600)	(-600)	(-600)	(-600)	(-600)	(-600)	(-600)	(-600)	(-600)	(-600)	(-600)	(-600)	(-600)	(-600)	(-600)	(-600)	(-600)	(-600)	(-600)	(-600)	(-600)	(-600)	(-600)	(-600)	(-600)	(-600)	(-600)	(-600)
				(-600)	(-600)	(-600)	(-600)	(-600)	(-600)	(-600)	(-600)	(-600)	(-600)	(-600)	(-600)	(-600)	(-600)	(-600)	(-600)	(-600)	(-600)	(-600)	(-600)	(-600)	(-600)	(-600)	(-600)	(-600)	(-600)	(-600)	(-600)	(-600)	(-600)	(-600)	(-600)
				(-600)	(-600)	(-600)	(-600)	(-600)	(-600)	(-600)	(-600)	(-600)	(-600)	(-600)	(-600)	(-600)	(-600)	(-600)	(-600)	(-600)	(-600)	(-600)	(-600)	(-600)	(-600)	(-600)	(-600)	(-600)	(-600)	(-600)	(-600)	(-600)	(-600)	(-600)	(-600)
				(-600)	(-600)	(-600)	(-600)	(-600)	(-600)	(-600)	(-600)	(-600)	(-600)	(-600)	(-600)	(-600)	(-600)	(-600)	(-600)	(-600)	(-600)	(-600)	(-600)	(-600)	(-600)	(-600)	(-600)	(-600)	(-600)	(-600)	(-600)	(-600)	(-600)	(-600)	(-600)>;

			PS_Config_Lmt_PenTipY_FW_Diff_P = <
				600	600	600	600
				600	600	600	600
				600	600	600	600
				600	600	600	600
				600	600	600	600
				600	600	600	600
				600	600	600	600
				600	600	600	600
				600	600	600	600
				600	600	600	600
				600	600	600	600
				600	600	600	600
				600	600	600	600
				600	600	600	600
				600	600	600	600
				600	600	600	600
				600	600	600	600
				600	600	600	600
				600	600	600	600
				600	600	600	600
				600	600	600	600
				600	600	600	600
				600	600	600	600
				600	600	600	600
				600	600	600	600
				600	600	600	600
				600	600	600	600
				600	600	600	600
				600	600	600	600
				600	600	600	600
				600	600	600	600
				600	600	600	600
				600	600	600	600
				600	600	600	600
				600	600	600	600
				600	600	600	600
				600	600	600	600
				600	600	600	600
				600	600	600	600
				600	600	600	600
				600	600	600	600
				600	600	600	600
				600	600	600	600
				600	600	600	600
				600	600	600	600
				600	600	600	600
				600	600	600	600
				600	600	600	600
				600	600	600	600
				600	600	600	600>;

			PS_Config_Lmt_PenTipY_FW_Diff_N = <
				(-600)	(-600)	(-600)	(-600)
				(-600)	(-600)	(-600)	(-600)
				(-600)	(-600)	(-600)	(-600)
				(-600)	(-600)	(-600)	(-600)
				(-600)	(-600)	(-600)	(-600)
				(-600)	(-600)	(-600)	(-600)
				(-600)	(-600)	(-600)	(-600)
				(-600)	(-600)	(-600)	(-600)
				(-600)	(-600)	(-600)	(-600)
				(-600)	(-600)	(-600)	(-600)
				(-600)	(-600)	(-600)	(-600)
				(-600)	(-600)	(-600)	(-600)
				(-600)	(-600)	(-600)	(-600)
				(-600)	(-600)	(-600)	(-600)
				(-600)	(-600)	(-600)	(-600)
				(-600)	(-600)	(-600)	(-600)
				(-600)	(-600)	(-600)	(-600)
				(-600)	(-600)	(-600)	(-600)
				(-600)	(-600)	(-600)	(-600)
				(-600)	(-600)	(-600)	(-600)
				(-600)	(-600)	(-600)	(-600)
				(-600)	(-600)	(-600)	(-600)
				(-600)	(-600)	(-600)	(-600)
				(-600)	(-600)	(-600)	(-600)
				(-600)	(-600)	(-600)	(-600)
				(-600)	(-600)	(-600)	(-600)
				(-600)	(-600)	(-600)	(-600)
				(-600)	(-600)	(-600)	(-600)
				(-600)	(-600)	(-600)	(-600)
				(-600)	(-600)	(-600)	(-600)
				(-600)	(-600)	(-600)	(-600)
				(-600)	(-600)	(-600)	(-600)
				(-600)	(-600)	(-600)	(-600)
				(-600)	(-600)	(-600)	(-600)
				(-600)	(-600)	(-600)	(-600)
				(-600)	(-600)	(-600)	(-600)
				(-600)	(-600)	(-600)	(-600)
				(-600)	(-600)	(-600)	(-600)
				(-600)	(-600)	(-600)	(-600)
				(-600)	(-600)	(-600)	(-600)
				(-600)	(-600)	(-600)	(-600)
				(-600)	(-600)	(-600)	(-600)
				(-600)	(-600)	(-600)	(-600)
				(-600)	(-600)	(-600)	(-600)
				(-600)	(-600)	(-600)	(-600)
				(-600)	(-600)	(-600)	(-600)
				(-600)	(-600)	(-600)	(-600)
				(-600)	(-600)	(-600)	(-600)
				(-600)	(-600)	(-600)	(-600)
				(-600)	(-600)	(-600)	(-600)>;

			PS_Config_Lmt_PenRingX_FW_Diff_P = <
				600	600	600	600	600	600	600	600	600	600	600	600	600	600	600	600	600	600	600	600	600	600	600	600	600	600	600	600	600	600	600	600
				600	600	600	600	600	600	600	600	600	600	600	600	600	600	600	600	600	600	600	600	600	600	600	600	600	600	600	600	600	600	600	600
				600	600	600	600	600	600	600	600	600	600	600	600	600	600	600	600	600	600	600	600	600	600	600	600	600	600	600	600	600	600	600	600
				600	600	600	600	600	600	600	600	600	600	600	600	600	600	600	600	600	600	600	600	600	600	600	600	600	600	600	600	600	600	600	600
				600	600	600	600	600	600	600	600	600	600	600	600	600	600	600	600	600	600	600	600	600	600	600	600	600	600	600	600	600	600	600	600
				600	600	600	600	600	600	600	600	600	600	600	600	600	600	600	600	600	600	600	600	600	600	600	600	600	600	600	600	600	600	600	600>;

			PS_Config_Lmt_PenRingX_FW_Diff_N = <
				(-600)	(-600)	(-600)	(-600)	(-600)	(-600)	(-600)	(-600)	(-600)	(-600)	(-600)	(-600)	(-600)	(-600)	(-600)	(-600)	(-600)	(-600)	(-600)	(-600)	(-600)	(-600)	(-600)	(-600)	(-600)	(-600)	(-600)	(-600)	(-600)	(-600)	(-600)	(-600)
				(-600)	(-600)	(-600)	(-600)	(-600)	(-600)	(-600)	(-600)	(-600)	(-600)	(-600)	(-600)	(-600)	(-600)	(-600)	(-600)	(-600)	(-600)	(-600)	(-600)	(-600)	(-600)	(-600)	(-600)	(-600)	(-600)	(-600)	(-600)	(-600)	(-600)	(-600)	(-600)
				(-600)	(-600)	(-600)	(-600)	(-600)	(-600)	(-600)	(-600)	(-600)	(-600)	(-600)	(-600)	(-600)	(-600)	(-600)	(-600)	(-600)	(-600)	(-600)	(-600)	(-600)	(-600)	(-600)	(-600)	(-600)	(-600)	(-600)	(-600)	(-600)	(-600)	(-600)	(-600)
				(-600)	(-600)	(-600)	(-600)	(-600)	(-600)	(-600)	(-600)	(-600)	(-600)	(-600)	(-600)	(-600)	(-600)	(-600)	(-600)	(-600)	(-600)	(-600)	(-600)	(-600)	(-600)	(-600)	(-600)	(-600)	(-600)	(-600)	(-600)	(-600)	(-600)	(-600)	(-600)
				(-600)	(-600)	(-600)	(-600)	(-600)	(-600)	(-600)	(-600)	(-600)	(-600)	(-600)	(-600)	(-600)	(-600)	(-600)	(-600)	(-600)	(-600)	(-600)	(-600)	(-600)	(-600)	(-600)	(-600)	(-600)	(-600)	(-600)	(-600)	(-600)	(-600)	(-600)	(-600)
				(-600)	(-600)	(-600)	(-600)	(-600)	(-600)	(-600)	(-600)	(-600)	(-600)	(-600)	(-600)	(-600)	(-600)	(-600)	(-600)	(-600)	(-600)	(-600)	(-600)	(-600)	(-600)	(-600)	(-600)	(-600)	(-600)	(-600)	(-600)	(-600)	(-600)	(-600)	(-600)>;

			PS_Config_Lmt_PenRingY_FW_Diff_P = <
				600	600	600	600
				600	600	600	600
				600	600	600	600
				600	600	600	600
				600	600	600	600
				600	600	600	600
				600	600	600	600
				600	600	600	600
				600	600	600	600
				600	600	600	600
				600	600	600	600
				600	600	600	600
				600	600	600	600
				600	600	600	600
				600	600	600	600
				600	600	600	600
				600	600	600	600
				600	600	600	600
				600	600	600	600
				600	600	600	600
				600	600	600	600
				600	600	600	600
				600	600	600	600
				600	600	600	600
				600	600	600	600
				600	600	600	600
				600	600	600	600
				600	600	600	600
				600	600	600	600
				600	600	600	600
				600	600	600	600
				600	600	600	600
				600	600	600	600
				600	600	600	600
				600	600	600	600
				600	600	600	600
				600	600	600	600
				600	600	600	600
				600	600	600	600
				600	600	600	600
				600	600	600	600
				600	600	600	600
				600	600	600	600
				600	600	600	600
				600	600	600	600
				600	600	600	600
				600	600	600	600
				600	600	600	600
				600	600	600	600
				600	600	600	600>;

			PS_Config_Lmt_PenRingY_FW_Diff_N = <
				(-600)	(-600)	(-600)	(-600)
				(-600)	(-600)	(-600)	(-600)
				(-600)	(-600)	(-600)	(-600)
				(-600)	(-600)	(-600)	(-600)
				(-600)	(-600)	(-600)	(-600)
				(-600)	(-600)	(-600)	(-600)
				(-600)	(-600)	(-600)	(-600)
				(-600)	(-600)	(-600)	(-600)
				(-600)	(-600)	(-600)	(-600)
				(-600)	(-600)	(-600)	(-600)
				(-600)	(-600)	(-600)	(-600)
				(-600)	(-600)	(-600)	(-600)
				(-600)	(-600)	(-600)	(-600)
				(-600)	(-600)	(-600)	(-600)
				(-600)	(-600)	(-600)	(-600)
				(-600)	(-600)	(-600)	(-600)
				(-600)	(-600)	(-600)	(-600)
				(-600)	(-600)	(-600)	(-600)
				(-600)	(-600)	(-600)	(-600)
				(-600)	(-600)	(-600)	(-600)
				(-600)	(-600)	(-600)	(-600)
				(-600)	(-600)	(-600)	(-600)
				(-600)	(-600)	(-600)	(-600)
				(-600)	(-600)	(-600)	(-600)
				(-600)	(-600)	(-600)	(-600)
				(-600)	(-600)	(-600)	(-600)
				(-600)	(-600)	(-600)	(-600)
				(-600)	(-600)	(-600)	(-600)
				(-600)	(-600)	(-600)	(-600)
				(-600)	(-600)	(-600)	(-600)
				(-600)	(-600)	(-600)	(-600)
				(-600)	(-600)	(-600)	(-600)
				(-600)	(-600)	(-600)	(-600)
				(-600)	(-600)	(-600)	(-600)
				(-600)	(-600)	(-600)	(-600)
				(-600)	(-600)	(-600)	(-600)
				(-600)	(-600)	(-600)	(-600)
				(-600)	(-600)	(-600)	(-600)
				(-600)	(-600)	(-600)	(-600)
				(-600)	(-600)	(-600)	(-600)
				(-600)	(-600)	(-600)	(-600)
				(-600)	(-600)	(-600)	(-600)
				(-600)	(-600)	(-600)	(-600)
				(-600)	(-600)	(-600)	(-600)
				(-600)	(-600)	(-600)	(-600)
				(-600)	(-600)	(-600)	(-600)
				(-600)	(-600)	(-600)	(-600)
				(-600)	(-600)	(-600)	(-600)
				(-600)	(-600)	(-600)	(-600)
				(-600)	(-600)	(-600)	(-600)>;

			PS_Config_Diff_Test_Frame = <50>;
		};
	};
};
